AUTOSAR XML (schema 4-1-3)
standard types defined: boolean, sint8, uint16, uint32, uint8, boolean_CompuMethod, boolean_DataConstr, sint8_DataConstr, uint16_DataConstr, uint32_DataConstr, uint8_DataConstr, sint16
package /MICROSAR/Dem_swc/DataTypes
  5 x impl type:
    Dem_DebounceResetStatusType: compu {0=DEM_DEBOUNCE_STATUS_FREEZE, 1=DEM_DEBOUNCE_STATUS_RESET}, range raw 0..255, implementation-data-type=ImplementationDataTypes/uint8
    Dem_DTCFormatType: compu {0=DEM_DTC_FORMAT_OBD, 1=DEM_DTC_FORMAT_UDS, 2=DEM_DTC_FORMAT_J1939}, range raw 0..2, implementation-data-type=ImplementationDataTypes/uint8
    Dem_EventStatusType:
      compu {0=DEM_EVENT_STATUS_PASSED, 1=DEM_EVENT_STATUS_FAILED, 2=DEM_EVENT_STATUS_PREPASSED, 3=DEM_EVENT_STATUS_PREFAILED, 4=DEM_EVENT_STATUS_FDC_THRESHOLD_REACHED, 5=DEM_EVENT_STATUS_PASSED_CONDITIONS_NOT_FULFILLED, 6=DEM_EVENT_STATUS_FAILED_CONDITIONS_NOT_FULFILLED, 7=DEM_EVENT_STATUS_PREPASSED_CONDITIONS_NOT_FULFILLED, 8=DEM_EVENT_STATUS_PREFAILED_CONDITIONS_NOT_FULFILLED}
      range raw 0..255
      implementation-data-type=ImplementationDataTypes/uint8
    Dem_MaxDataValueType: category=ARRAY, sw-calibration-access=READ-ONLY
      element Dem_MaxDataValueTypeElement: array-size=14, array-size-semantics=FIXED-SIZE, implementation-data-type=ImplementationDataTypes/uint8
    Dem_UdsStatusByteType:
      compu {mask 1: 1=DEM_UDS_STATUS_TF (bit 0: TestFailed), mask 2: 2=DEM_UDS_STATUS_TFTOC (bit 1: TestFailedThisOperationCycle), mask 4: 4=DEM_UDS_STATUS_PDTC (bit 2: PendingDTC), mask 8: 8=DEM_UDS_STATUS_CDTC (bit 3: ConfirmedDTC), mask 16: 16=DEM_UDS_STATUS_TNCSLC (bit 4: TestNotCompletedSinceLastClear), mask 32: 32=DEM_UDS_STATUS_TFSLC (bit 5: TestFailedSinceLastClear), mask 64: 64=DEM_UDS_STATUS_TNCTOC (bit 6: TestNotCompletedThisOperationCycle), mask 128: 128=DEM_UDS_STATUS_WIR (bit 7: WarningIndicatorRequested)}
      range raw 0..255
      implementation-data-type=ImplementationDataTypes/uint8
package /MICROSAR/Dem_swc/Interfaces
  client server interface DiagnosticMonitor: is-service=true, service-kind=DIAGNOSTIC-EVENT-MANAGER
    11 x operation:
      GetDTCOfEvent: possible-error=[DEM_E_NO_DTC_AVAILABLE, E_NOT_OK]
        arg DTCFormat: type=Dem_DTCFormatType, direction=IN, server-argument-impl-policy=USE-ARGUMENT-TYPE
        arg DTCOfEvent: type=uint32, direction=OUT, server-argument-impl-policy=USE-ARGUMENT-TYPE
      GetEventExtendedDataRecordEx: possible-error=[DEM_BUFFER_TOO_SMALL, DEM_NO_SUCH_ELEMENT, E_NOT_OK]
        arg RecordNumber: type=ImplementationDataTypes/uint8, direction=IN, server-argument-impl-policy=USE-ARGUMENT-TYPE
        arg DestBuffer: type=Dem_MaxDataValueType, direction=OUT, server-argument-impl-policy=USE-ARGUMENT-TYPE
        arg BufSize: type=ImplementationDataTypes/uint16, direction=INOUT, server-argument-impl-policy=USE-ARGUMENT-TYPE
      GetEventFailed: possible-error=E_NOT_OK
        arg EventFailed: type=ImplementationDataTypes/boolean, direction=OUT, server-argument-impl-policy=USE-ARGUMENT-TYPE
      GetEventFreezeFrameDataEx: possible-error=[DEM_BUFFER_TOO_SMALL, DEM_NO_SUCH_ELEMENT, E_NOT_OK]
        4 x arg, all with server-argument-impl-policy=USE-ARGUMENT-TYPE:
          RecordNumber: type=ImplementationDataTypes/uint8, direction=IN
          DataId: type=ImplementationDataTypes/uint16, direction=IN
          DestBuffer: type=Dem_MaxDataValueType, direction=OUT
          BufSize: type=ImplementationDataTypes/uint16, direction=INOUT
      GetEventStatus: possible-error=E_NOT_OK
        arg UDSStatusByte: type=Dem_UdsStatusByteType, direction=OUT, server-argument-impl-policy=USE-ARGUMENT-TYPE
      GetEventTested: possible-error=E_NOT_OK
        arg EventTested: type=ImplementationDataTypes/boolean, direction=OUT, server-argument-impl-policy=USE-ARGUMENT-TYPE
      GetEventUdsStatus: possible-error=E_NOT_OK
        arg UDSStatusByte: type=Dem_UdsStatusByteType, direction=OUT, server-argument-impl-policy=USE-ARGUMENT-TYPE
      GetFaultDetectionCounter: possible-error=[DEM_E_NO_FDC_AVAILABLE, E_NOT_OK]
        arg FaultDetectionCounter: type=sint8, direction=OUT, server-argument-impl-policy=USE-ARGUMENT-TYPE
      ResetEventDebounceStatus: possible-error=E_NOT_OK
        arg DebounceResetStatus: type=Dem_DebounceResetStatusType, direction=IN, server-argument-impl-policy=USE-ARGUMENT-TYPE
      ResetEventStatus: possible-error=E_NOT_OK
      SetEventStatus: possible-error=E_NOT_OK
        arg EventStatus: type=Dem_EventStatusType, direction=IN, server-argument-impl-policy=USE-ARGUMENT-TYPE
    5 x error:
      DEM_BUFFER_TOO_SMALL: error-code=21
      DEM_E_NO_DTC_AVAILABLE: error-code=10
      DEM_E_NO_FDC_AVAILABLE: error-code=14
      DEM_NO_SUCH_ELEMENT: error-code=48
      E_NOT_OK: error-code=1
package /UAES/ASW/ApplicationDataTypes
  app type T_q0p1_o273p14_DegC_s16: category=VALUE, sw-calibration-access=READ-WRITE, compu {phys=raw*0.1-273.14 for raw -INF..INF; unit DegC}, range raw -32768..32767
package /UAES/ASW/CompuMethods
  compu method CM_boolean: 0=FALSE, 1=TRUE
package /UAES/ASW/DataConstrs
  range DC_boolean: raw 0..1
  range DC_sint16: raw -32768..32767
  range DC_uint16: phys 0..6553.5, raw 0..65535
package /UAES/ASW/DataTypeMappingSets
  data type mapping set DTMS_HVAC_ComCnvTx: data-type-map{application-data-type=T_q0p1_o273p14_DegC_s16, implementation-data-type=sint16}
package /UAES/ASW/PortInterfaces
  147 x sender receiver interface:
    CabinT_t: invalidation-policy{data-element=CabinT_t/Val, handle-invalid=DONT-INVALIDATE}
      data Val: sw-calibration-access=READ-ONLY, type=T_q0p1_o273p14_DegC_s16
    CabinT_tRe: invalidation-policy{data-element=CabinT_tRe/Val, handle-invalid=DONT-INVALIDATE}
      data Val: sw-calibration-access=READ-ONLY, type=T_q0p1_o273p14_DegC_s16
    ComRx_u8UMM_UsageModeSt: invalidation-policy{data-element=ComRx_u8UMM_UsageModeSt/Val, handle-invalid=DONT-INVALIDATE}
      data Val: sw-calibration-access=READ-ONLY, type=ImplementationDataTypes/uint8
    ComTx_bHVAC_LeftExtMirrorHeatActSt: invalidation-policy{data-element=ComTx_bHVAC_LeftExtMirrorHeatActSt/Val, handle-invalid=DONT-INVALIDATE}
      data Val: sw-calibration-access=READ-ONLY, type=ImplementationDataTypes/boolean
    ComTx_bHVAC_ModeServoSt: invalidation-policy{data-element=ComTx_bHVAC_ModeServoSt/Val, handle-invalid=DONT-INVALIDATE}
      data Val: sw-calibration-access=READ-ONLY, type=ImplementationDataTypes/boolean
    ComTx_bHVAC_RearDefrostActSt: invalidation-policy{data-element=ComTx_bHVAC_RearDefrostActSt/Val, handle-invalid=DONT-INVALIDATE}
      data Val: sw-calibration-access=READ-ONLY, type=ImplementationDataTypes/boolean
    ComTx_bHVAC_RightExtMirrorHeatActSt: invalidation-policy{data-element=ComTx_bHVAC_RightExtMirrorHeatActSt/Val, handle-invalid=DONT-INVALIDATE}
      data Val: sw-calibration-access=READ-ONLY, type=ImplementationDataTypes/boolean
    ComTx_bHVAC_RrAMDoorPostionVD: invalidation-policy{data-element=ComTx_bHVAC_RrAMDoorPostionVD/Val, handle-invalid=DONT-INVALIDATE}
      data Val: sw-calibration-access=READ-ONLY, type=ImplementationDataTypes/boolean
    ComTx_bHVAC_RrBlowerPowerSt: invalidation-policy{data-element=ComTx_bHVAC_RrBlowerPowerSt/Val, handle-invalid=DONT-INVALIDATE}
      data Val: sw-calibration-access=READ-ONLY, type=ImplementationDataTypes/boolean
    ComTx_bHVAC_RrModeServoSt: invalidation-policy{data-element=ComTx_bHVAC_RrModeServoSt/Val, handle-invalid=DONT-INVALIDATE}
      data Val: sw-calibration-access=READ-ONLY, type=ImplementationDataTypes/boolean
    ComTx_u16HVAC_DrFaceOutletTemp: invalidation-policy{data-element=ComTx_u16HVAC_DrFaceOutletTemp/Val, handle-invalid=DONT-INVALIDATE}
      data Val: sw-calibration-access=READ-ONLY, type=ImplementationDataTypes/uint16
    ComTx_u16HVAC_DrFootOutletTemp: invalidation-policy{data-element=ComTx_u16HVAC_DrFootOutletTemp/Val, handle-invalid=DONT-INVALIDATE}
      data Val: sw-calibration-access=READ-ONLY, type=ImplementationDataTypes/uint16
    ComTx_u16HVAC_PaFaceOutletTemp: invalidation-policy{data-element=ComTx_u16HVAC_PaFaceOutletTemp/Val, handle-invalid=DONT-INVALIDATE}
      data Val: sw-calibration-access=READ-ONLY, type=ImplementationDataTypes/uint16
    ComTx_u16HVAC_PaFootOutletTemp: invalidation-policy{data-element=ComTx_u16HVAC_PaFootOutletTemp/Val, handle-invalid=DONT-INVALIDATE}
      data Val: sw-calibration-access=READ-ONLY, type=ImplementationDataTypes/uint16
    ComTx_u16HVAC_RawCabinTemp: invalidation-policy{data-element=ComTx_u16HVAC_RawCabinTemp/Val, handle-invalid=DONT-INVALIDATE}
      data Val: sw-calibration-access=READ-ONLY, type=ImplementationDataTypes/uint16
    ComTx_u16HVAC_RawEvaTemp: invalidation-policy{data-element=ComTx_u16HVAC_RawEvaTemp/Val, handle-invalid=DONT-INVALIDATE}
      data Val: sw-calibration-access=READ-ONLY, type=ImplementationDataTypes/uint16
    ComTx_u16HVAC_RrRawCabinTemp: invalidation-policy{data-element=ComTx_u16HVAC_RrRawCabinTemp/Val, handle-invalid=DONT-INVALIDATE}
      data Val: sw-calibration-access=READ-ONLY, type=ImplementationDataTypes/uint16
    ComTx_u16HVAC_RrRawEvaTemp: invalidation-policy{data-element=ComTx_u16HVAC_RrRawEvaTemp/Val, handle-invalid=DONT-INVALIDATE}
      data Val: sw-calibration-access=READ-ONLY, type=ImplementationDataTypes/uint16
    ComTx_u8HVAC_AirCirculationAct: invalidation-policy{data-element=ComTx_u8HVAC_AirCirculationAct/Val, handle-invalid=DONT-INVALIDATE}
      data Val: sw-calibration-access=READ-ONLY, type=ImplementationDataTypes/uint8
    ComTx_u8HVAC_CirculationServoFault: invalidation-policy{data-element=ComTx_u8HVAC_CirculationServoFault/Val, handle-invalid=DONT-INVALIDATE}
      data Val: sw-calibration-access=READ-ONLY, type=ImplementationDataTypes/uint8
    ComTx_u8HVAC_CirculationServoFB: invalidation-policy{data-element=ComTx_u8HVAC_CirculationServoFB/Val, handle-invalid=DONT-INVALIDATE}
      data Val: sw-calibration-access=READ-ONLY, type=ImplementationDataTypes/uint8
    ComTx_u8HVAC_DrAirCirculationAct: invalidation-policy{data-element=ComTx_u8HVAC_DrAirCirculationAct/Val, handle-invalid=DONT-INVALIDATE}
      data Val: sw-calibration-access=READ-ONLY, type=ImplementationDataTypes/uint8
    ComTx_u8HVAC_DrAirCirculationServoFault: invalidation-policy{data-element=ComTx_u8HVAC_DrAirCirculationServoFault/Val, handle-invalid=DONT-INVALIDATE}
      data Val: sw-calibration-access=READ-ONLY, type=ImplementationDataTypes/uint8
    ComTx_u8HVAC_DrAirCirculationServoFB: invalidation-policy{data-element=ComTx_u8HVAC_DrAirCirculationServoFB/Val, handle-invalid=DONT-INVALIDATE}
      data Val: sw-calibration-access=READ-ONLY, type=ImplementationDataTypes/uint8
    ComTx_u8HVAC_DrAMDoorPostionAct: invalidation-policy{data-element=ComTx_u8HVAC_DrAMDoorPostionAct/Val, handle-invalid=DONT-INVALIDATE}
      data Val: sw-calibration-access=READ-ONLY, type=ImplementationDataTypes/uint8
    ComTx_u8HVAC_DrAMServoFault: invalidation-policy{data-element=ComTx_u8HVAC_DrAMServoFault/Val, handle-invalid=DONT-INVALIDATE}
      data Val: sw-calibration-access=READ-ONLY, type=ImplementationDataTypes/uint8
    ComTx_u8HVAC_DrAMServoFB: invalidation-policy{data-element=ComTx_u8HVAC_DrAMServoFB/Val, handle-invalid=DONT-INVALIDATE}
      data Val: sw-calibration-access=READ-ONLY, type=ImplementationDataTypes/uint8
    ComTx_u8HVAC_DrFaceOutletTempFault: invalidation-policy{data-element=ComTx_u8HVAC_DrFaceOutletTempFault/Val, handle-invalid=DONT-INVALIDATE}
      data Val: sw-calibration-access=READ-ONLY, type=ImplementationDataTypes/uint8
    ComTx_u8HVAC_DrFootOutletTempFault: invalidation-policy{data-element=ComTx_u8HVAC_DrFootOutletTempFault/Val, handle-invalid=DONT-INVALIDATE}
      data Val: sw-calibration-access=READ-ONLY, type=ImplementationDataTypes/uint8
    ComTx_u8HVAC_ModeServoFault: invalidation-policy{data-element=ComTx_u8HVAC_ModeServoFault/Val, handle-invalid=DONT-INVALIDATE}
      data Val: sw-calibration-access=READ-ONLY, type=ImplementationDataTypes/uint8
    ComTx_u8HVAC_ModeServoFB: invalidation-policy{data-element=ComTx_u8HVAC_ModeServoFB/Val, handle-invalid=DONT-INVALIDATE}
      data Val: sw-calibration-access=READ-ONLY, type=ImplementationDataTypes/uint8
    ComTx_u8HVAC_PaAirCirculationAct: invalidation-policy{data-element=ComTx_u8HVAC_PaAirCirculationAct/Val, handle-invalid=DONT-INVALIDATE}
      data Val: sw-calibration-access=READ-ONLY, type=ImplementationDataTypes/uint8
    ComTx_u8HVAC_PaAirCirculationServoFault: invalidation-policy{data-element=ComTx_u8HVAC_PaAirCirculationServoFault/Val, handle-invalid=DONT-INVALIDATE}
      data Val: sw-calibration-access=READ-ONLY, type=ImplementationDataTypes/uint8
    ComTx_u8HVAC_PaAirCirculationServoFB: invalidation-policy{data-element=ComTx_u8HVAC_PaAirCirculationServoFB/Val, handle-invalid=DONT-INVALIDATE}
      data Val: sw-calibration-access=READ-ONLY, type=ImplementationDataTypes/uint8
    ComTx_u8HVAC_PaAMDoorPostionAct: invalidation-policy{data-element=ComTx_u8HVAC_PaAMDoorPostionAct/Val, handle-invalid=DONT-INVALIDATE}
      data Val: sw-calibration-access=READ-ONLY, type=ImplementationDataTypes/uint8
    ComTx_u8HVAC_PaAMServoFault: invalidation-policy{data-element=ComTx_u8HVAC_PaAMServoFault/Val, handle-invalid=DONT-INVALIDATE}
      data Val: sw-calibration-access=READ-ONLY, type=ImplementationDataTypes/uint8
    ComTx_u8HVAC_PaAMServoFB: invalidation-policy{data-element=ComTx_u8HVAC_PaAMServoFB/Val, handle-invalid=DONT-INVALIDATE}
      data Val: sw-calibration-access=READ-ONLY, type=ImplementationDataTypes/uint8
    ComTx_u8HVAC_PaFaceOutletTempFault: invalidation-policy{data-element=ComTx_u8HVAC_PaFaceOutletTempFault/Val, handle-invalid=DONT-INVALIDATE}
      data Val: sw-calibration-access=READ-ONLY, type=ImplementationDataTypes/uint8
    ComTx_u8HVAC_PaFootOutletTempFault: invalidation-policy{data-element=ComTx_u8HVAC_PaFootOutletTempFault/Val, handle-invalid=DONT-INVALIDATE}
      data Val: sw-calibration-access=READ-ONLY, type=ImplementationDataTypes/uint8
    ComTx_u8HVAC_RawCabinTempFault: invalidation-policy{data-element=ComTx_u8HVAC_RawCabinTempFault/Val, handle-invalid=DONT-INVALIDATE}
      data Val: sw-calibration-access=READ-ONLY, type=ImplementationDataTypes/uint8
    ComTx_u8HVAC_RawEvaTempFault: invalidation-policy{data-element=ComTx_u8HVAC_RawEvaTempFault/Val, handle-invalid=DONT-INVALIDATE}
      data Val: sw-calibration-access=READ-ONLY, type=ImplementationDataTypes/uint8
    ComTx_u8HVAC_RrAMDoorPostion: invalidation-policy{data-element=ComTx_u8HVAC_RrAMDoorPostion/Val, handle-invalid=DONT-INVALIDATE}
      data Val: sw-calibration-access=READ-ONLY, type=ImplementationDataTypes/uint8
    ComTx_u8HVAC_RrAMDoorPostionAct: invalidation-policy{data-element=ComTx_u8HVAC_RrAMDoorPostionAct/Val, handle-invalid=DONT-INVALIDATE}
      data Val: sw-calibration-access=READ-ONLY, type=ImplementationDataTypes/uint8
    ComTx_u8HVAC_RrAMServoFault: invalidation-policy{data-element=ComTx_u8HVAC_RrAMServoFault/Val, handle-invalid=DONT-INVALIDATE}
      data Val: sw-calibration-access=READ-ONLY, type=ImplementationDataTypes/uint8
    ComTx_u8HVAC_RrAMServoFB: invalidation-policy{data-element=ComTx_u8HVAC_RrAMServoFB/Val, handle-invalid=DONT-INVALIDATE}
      data Val: sw-calibration-access=READ-ONLY, type=ImplementationDataTypes/uint8
    ComTx_u8HVAC_RrModeServoFault: invalidation-policy{data-element=ComTx_u8HVAC_RrModeServoFault/Val, handle-invalid=DONT-INVALIDATE}
      data Val: sw-calibration-access=READ-ONLY, type=ImplementationDataTypes/uint8
    ComTx_u8HVAC_RrModeServoFB: invalidation-policy{data-element=ComTx_u8HVAC_RrModeServoFB/Val, handle-invalid=DONT-INVALIDATE}
      data Val: sw-calibration-access=READ-ONLY, type=ImplementationDataTypes/uint8
    ComTx_u8HVAC_RrRawCabinTempFault: invalidation-policy{data-element=ComTx_u8HVAC_RrRawCabinTempFault/Val, handle-invalid=DONT-INVALIDATE}
      data Val: sw-calibration-access=READ-ONLY, type=ImplementationDataTypes/uint8
    ComTx_u8HVAC_RrRawEvaTempFault: invalidation-policy{data-element=ComTx_u8HVAC_RrRawEvaTempFault/Val, handle-invalid=DONT-INVALIDATE}
      data Val: sw-calibration-access=READ-ONLY, type=ImplementationDataTypes/uint8
    ComTx_u8HVAC_RrWindExitModeAct: invalidation-policy{data-element=ComTx_u8HVAC_RrWindExitModeAct/Val, handle-invalid=DONT-INVALIDATE}
      data Val: sw-calibration-access=READ-ONLY, type=ImplementationDataTypes/uint8
    ComTx_u8HVAC_RrWindExitSpdLvlAct: invalidation-policy{data-element=ComTx_u8HVAC_RrWindExitSpdLvlAct/Val, handle-invalid=DONT-INVALIDATE}
      data Val: sw-calibration-access=READ-ONLY, type=ImplementationDataTypes/uint8
    ComTx_u8HVAC_SolarValueLeft: invalidation-policy{data-element=ComTx_u8HVAC_SolarValueLeft/Val, handle-invalid=DONT-INVALIDATE}
      data Val: sw-calibration-access=READ-ONLY, type=ImplementationDataTypes/uint8
    ComTx_u8HVAC_SolarValueLeftFault: invalidation-policy{data-element=ComTx_u8HVAC_SolarValueLeftFault/Val, handle-invalid=DONT-INVALIDATE}
      data Val: sw-calibration-access=READ-ONLY, type=ImplementationDataTypes/uint8
    ComTx_u8HVAC_SolarValueRight: invalidation-policy{data-element=ComTx_u8HVAC_SolarValueRight/Val, handle-invalid=DONT-INVALIDATE}
      data Val: sw-calibration-access=READ-ONLY, type=ImplementationDataTypes/uint8
    ComTx_u8HVAC_SolarValueRightFault: invalidation-policy{data-element=ComTx_u8HVAC_SolarValueRightFault/Val, handle-invalid=DONT-INVALIDATE}
      data Val: sw-calibration-access=READ-ONLY, type=ImplementationDataTypes/uint8
    ComTx_u8HVAC_WindExitModeAct: invalidation-policy{data-element=ComTx_u8HVAC_WindExitModeAct/Val, handle-invalid=DONT-INVALIDATE}
      data Val: sw-calibration-access=READ-ONLY, type=ImplementationDataTypes/uint8
    ComTx_u8HVAC_WindExitSpdLvlAct: invalidation-policy{data-element=ComTx_u8HVAC_WindExitSpdLvlAct/Val, handle-invalid=DONT-INVALIDATE}
      data Val: sw-calibration-access=READ-ONLY, type=ImplementationDataTypes/uint8
    EvaprT_t: invalidation-policy{data-element=EvaprT_t/Val, handle-invalid=DONT-INVALIDATE}
      data Val: sw-calibration-access=READ-ONLY, type=T_q0p1_o273p14_DegC_s16
    EvaprT_tRe: invalidation-policy{data-element=EvaprT_tRe/Val, handle-invalid=DONT-INVALIDATE}
      data Val: sw-calibration-access=READ-ONLY, type=T_q0p1_o273p14_DegC_s16
    gASI_bCCULostCommon: invalidation-policy{data-element=gASI_bCCULostCommon/Val, handle-invalid=DONT-INVALIDATE}
      data Val: sw-calibration-access=READ-ONLY, type=ImplementationDataTypes/boolean
    gCFG_bCabinTSnsrAvl: invalidation-policy{data-element=gCFG_bCabinTSnsrAvl/Val, handle-invalid=DONT-INVALIDATE}
      data Val: sw-calibration-access=READ-ONLY, type=ImplementationDataTypes/boolean
    gCFG_bReCabinTSnsrAvl: invalidation-policy{data-element=gCFG_bReCabinTSnsrAvl/Val, handle-invalid=DONT-INVALIDATE}
      data Val: sw-calibration-access=READ-ONLY, type=ImplementationDataTypes/boolean
    gCFG_u8AirVentTSnsrTyp: invalidation-policy{data-element=gCFG_u8AirVentTSnsrTyp/Val, handle-invalid=DONT-INVALIDATE}
      data Val: sw-calibration-access=READ-ONLY, type=ImplementationDataTypes/uint8
    gCFG_u8BlowrCtrlFreqTyp: invalidation-policy{data-element=gCFG_u8BlowrCtrlFreqTyp/Val, handle-invalid=DONT-INVALIDATE}
      data Val: sw-calibration-access=READ-ONLY, type=ImplementationDataTypes/uint8
    gCFG_u8BlowrCtrlTyp: invalidation-policy{data-element=gCFG_u8BlowrCtrlTyp/Val, handle-invalid=DONT-INVALIDATE}
      data Val: sw-calibration-access=READ-ONLY, type=ImplementationDataTypes/uint8
    gCFG_u8ReBlowrCtrlFreqTyp: invalidation-policy{data-element=gCFG_u8ReBlowrCtrlFreqTyp/Val, handle-invalid=DONT-INVALIDATE}
      data Val: sw-calibration-access=READ-ONLY, type=ImplementationDataTypes/uint8
    gCFG_u8ReBlowrCtrlTyp: invalidation-policy{data-element=gCFG_u8ReBlowrCtrlTyp/Val, handle-invalid=DONT-INVALIDATE}
      data Val: sw-calibration-access=READ-ONLY, type=ImplementationDataTypes/uint8
    gCFG_u8ReHVACBoxTyp: invalidation-policy{data-element=gCFG_u8ReHVACBoxTyp/Val, handle-invalid=DONT-INVALIDATE}
      data Val: sw-calibration-access=READ-ONLY, type=ImplementationDataTypes/uint8
    gPRM_bHotpumpCfg: invalidation-policy{data-element=gPRM_bHotpumpCfg/Val, handle-invalid=DONT-INVALIDATE}
      data Val: sw-calibration-access=READ-ONLY, type=ImplementationDataTypes/boolean
    gPRM_bSolarSnsrvalidPrm: invalidation-policy{data-element=gPRM_bSolarSnsrvalidPrm/Val, handle-invalid=DONT-INVALIDATE}
      data Val: sw-calibration-access=READ-ONLY, type=ImplementationDataTypes/boolean
    gPRM_u8AirConditionBoxSpecCfg: invalidation-policy{data-element=gPRM_u8AirConditionBoxSpecCfg/Val, handle-invalid=DONT-INVALIDATE}
      data Val: sw-calibration-access=READ-ONLY, type=ImplementationDataTypes/uint8
    gPRM_u8ReAirConditionBoxSpecCfg: invalidation-policy{data-element=gPRM_u8ReAirConditionBoxSpecCfg/Val, handle-invalid=DONT-INVALIDATE}
      data Val: sw-calibration-access=READ-ONLY, type=ImplementationDataTypes/uint8
    gPRM_u8VehicleTypeCfg: invalidation-policy{data-element=gPRM_u8VehicleTypeCfg/Val, handle-invalid=DONT-INVALIDATE}
      data Val: sw-calibration-access=READ-ONLY, range raw 0..255, type=ImplementationDataTypes/uint8
    HvacBlowr_bLPMBlowrEna: invalidation-policy{data-element=HvacBlowr_bLPMBlowrEna/Val, handle-invalid=DONT-INVALIDATE}
      data Val: sw-calibration-access=READ-ONLY, type=ImplementationDataTypes/boolean
    HvacBlowr_bReLPMBlowrEna: invalidation-policy{data-element=HvacBlowr_bReLPMBlowrEna/Val, handle-invalid=DONT-INVALIDATE}
      data Val: sw-calibration-access=READ-ONLY, type=ImplementationDataTypes/boolean
    HvacBlowr_freqPWMBlowr: invalidation-policy{data-element=HvacBlowr_freqPWMBlowr/Val, handle-invalid=DONT-INVALIDATE}
      data Val: sw-calibration-access=READ-ONLY, type=ImplementationDataTypes/uint16
    HvacBlowr_freqRePWMBlowr: invalidation-policy{data-element=HvacBlowr_freqRePWMBlowr/Val, handle-invalid=DONT-INVALIDATE}
      data Val: sw-calibration-access=READ-ONLY, type=ImplementationDataTypes/uint16
    HvacBlowr_prcTarFrntBlowrUds: invalidation-policy{data-element=HvacBlowr_prcTarFrntBlowrUds/Val, handle-invalid=DONT-INVALIDATE}
      data Val: sw-calibration-access=READ-ONLY, type=ImplementationDataTypes/uint8
    HvacBlowr_ratLPMBlowr: invalidation-policy{data-element=HvacBlowr_ratLPMBlowr/Val, handle-invalid=DONT-INVALIDATE}
      data Val: sw-calibration-access=READ-ONLY, type=ImplementationDataTypes/uint16
    HvacBlowr_ratPWMBlowr: invalidation-policy{data-element=HvacBlowr_ratPWMBlowr/Val, handle-invalid=DONT-INVALIDATE}
      data Val: sw-calibration-access=READ-ONLY, type=ImplementationDataTypes/uint16
    HvacBlowr_ratReLPMBlowr: invalidation-policy{data-element=HvacBlowr_ratReLPMBlowr/Val, handle-invalid=DONT-INVALIDATE}
      data Val: sw-calibration-access=READ-ONLY, type=ImplementationDataTypes/uint16
    HvacBlowr_ratRePWMBlowr: invalidation-policy{data-element=HvacBlowr_ratRePWMBlowr/Val, handle-invalid=DONT-INVALIDATE}
      data Val: sw-calibration-access=READ-ONLY, type=ImplementationDataTypes/uint16
    HvacBlowr_stReWindExitSpdLvlAct: invalidation-policy{data-element=HvacBlowr_stReWindExitSpdLvlAct/Val, handle-invalid=DONT-INVALIDATE}
      data Val: sw-calibration-access=READ-ONLY, type=ImplementationDataTypes/uint8
    HvacBlowr_stWindExitSpdLvlAct: invalidation-policy{data-element=HvacBlowr_stWindExitSpdLvlAct/Val, handle-invalid=DONT-INVALIDATE}
      data Val: sw-calibration-access=READ-ONLY, type=ImplementationDataTypes/uint16
    HvacBlowr_uRawLPMFb: invalidation-policy{data-element=HvacBlowr_uRawLPMFb/Val, handle-invalid=DONT-INVALIDATE}
      data Val: sw-calibration-access=READ-ONLY, type=ImplementationDataTypes/uint16
    HvacBlowr_uTarFrntBlowrUds: invalidation-policy{data-element=HvacBlowr_uTarFrntBlowrUds/Val, handle-invalid=DONT-INVALIDATE}
      data Val: sw-calibration-access=READ-ONLY, type=ImplementationDataTypes/uint8
    HvacDampr_stDrvrMixMotAct: invalidation-policy{data-element=HvacDampr_stDrvrMixMotAct/Val, handle-invalid=DONT-INVALIDATE}
      data Val: sw-calibration-access=READ-ONLY, type=ImplementationDataTypes/uint8
    HvacDampr_stDrvrMixMotDir: invalidation-policy{data-element=HvacDampr_stDrvrMixMotDir/Val, handle-invalid=DONT-INVALIDATE}
      data Val: sw-calibration-access=READ-ONLY, type=ImplementationDataTypes/uint8
    HvacDampr_stDrvrMixMotFlt: invalidation-policy{data-element=HvacDampr_stDrvrMixMotFlt/Val, handle-invalid=DONT-INVALIDATE}
      data Val: sw-calibration-access=READ-ONLY, type=ImplementationDataTypes/uint8
    HvacDampr_stDrvrMixMotRunng: invalidation-policy{data-element=HvacDampr_stDrvrMixMotRunng/Val, handle-invalid=DONT-INVALIDATE}
      data Val: sw-calibration-access=READ-ONLY, type=ImplementationDataTypes/uint8
    HvacDampr_stDrvrRcrltnMotAct: invalidation-policy{data-element=HvacDampr_stDrvrRcrltnMotAct/Val, handle-invalid=DONT-INVALIDATE}
      data Val: sw-calibration-access=READ-ONLY, type=ImplementationDataTypes/uint8
    HvacDampr_stDrvrRcrltnMotDir: invalidation-policy{data-element=HvacDampr_stDrvrRcrltnMotDir/Val, handle-invalid=DONT-INVALIDATE}
      data Val: sw-calibration-access=READ-ONLY, type=ImplementationDataTypes/uint8
    HvacDampr_stDrvrRcrltnMotFlt: invalidation-policy{data-element=HvacDampr_stDrvrRcrltnMotFlt/Val, handle-invalid=DONT-INVALIDATE}
      data Val: sw-calibration-access=READ-ONLY, type=ImplementationDataTypes/uint8
    HvacDampr_stDrvrRcrltnMotRunng: invalidation-policy{data-element=HvacDampr_stDrvrRcrltnMotRunng/Val, handle-invalid=DONT-INVALIDATE}
      data Val: sw-calibration-access=READ-ONLY, type=ImplementationDataTypes/uint8
    HvacDampr_stModMotAct: invalidation-policy{data-element=HvacDampr_stModMotAct/Val, handle-invalid=DONT-INVALIDATE}
      data Val: sw-calibration-access=READ-ONLY, type=ImplementationDataTypes/uint8
    HvacDampr_stModMotDir: invalidation-policy{data-element=HvacDampr_stModMotDir/Val, handle-invalid=DONT-INVALIDATE}
      data Val: sw-calibration-access=READ-ONLY, type=ImplementationDataTypes/uint8
    HvacDampr_stModMotFlt: invalidation-policy{data-element=HvacDampr_stModMotFlt/Val, handle-invalid=DONT-INVALIDATE}
      data Val: sw-calibration-access=READ-ONLY, type=ImplementationDataTypes/uint8
    HvacDampr_stModMotRunng: invalidation-policy{data-element=HvacDampr_stModMotRunng/Val, handle-invalid=DONT-INVALIDATE}
      data Val: sw-calibration-access=READ-ONLY, type=ImplementationDataTypes/uint8
    HvacDampr_stPassMixMotAct: invalidation-policy{data-element=HvacDampr_stPassMixMotAct/Val, handle-invalid=DONT-INVALIDATE}
      data Val: sw-calibration-access=READ-ONLY, type=ImplementationDataTypes/uint8
    HvacDampr_stPassMixMotDir: invalidation-policy{data-element=HvacDampr_stPassMixMotDir/Val, handle-invalid=DONT-INVALIDATE}
      data Val: sw-calibration-access=READ-ONLY, type=ImplementationDataTypes/uint8
    HvacDampr_stPassMixMotFlt: invalidation-policy{data-element=HvacDampr_stPassMixMotFlt/Val, handle-invalid=DONT-INVALIDATE}
      data Val: sw-calibration-access=READ-ONLY, type=ImplementationDataTypes/uint8
    HvacDampr_stPassMixMotRunng: invalidation-policy{data-element=HvacDampr_stPassMixMotRunng/Val, handle-invalid=DONT-INVALIDATE}
      data Val: sw-calibration-access=READ-ONLY, type=ImplementationDataTypes/uint8
    HvacDampr_stPassRcrltnMotAct: invalidation-policy{data-element=HvacDampr_stPassRcrltnMotAct/Val, handle-invalid=DONT-INVALIDATE}
      data Val: sw-calibration-access=READ-ONLY, type=ImplementationDataTypes/uint8
    HvacDampr_stPassRcrltnMotDir: invalidation-policy{data-element=HvacDampr_stPassRcrltnMotDir/Val, handle-invalid=DONT-INVALIDATE}
      data Val: sw-calibration-access=READ-ONLY, type=ImplementationDataTypes/uint8
    HvacDampr_stPassRcrltnMotFlt: invalidation-policy{data-element=HvacDampr_stPassRcrltnMotFlt/Val, handle-invalid=DONT-INVALIDATE}
      data Val: sw-calibration-access=READ-ONLY, type=ImplementationDataTypes/uint8
    HvacDampr_stPassRcrltnMotRunng: invalidation-policy{data-element=HvacDampr_stPassRcrltnMotRunng/Val, handle-invalid=DONT-INVALIDATE}
      data Val: sw-calibration-access=READ-ONLY, type=ImplementationDataTypes/uint8
    HvacDampr_stRcrltnMotAct: invalidation-policy{data-element=HvacDampr_stRcrltnMotAct/Val, handle-invalid=DONT-INVALIDATE}
      data Val: sw-calibration-access=READ-ONLY, type=ImplementationDataTypes/uint8
    HvacDampr_stRcrltnMotDir: invalidation-policy{data-element=HvacDampr_stRcrltnMotDir/Val, handle-invalid=DONT-INVALIDATE}
      data Val: sw-calibration-access=READ-ONLY, type=ImplementationDataTypes/uint8
    HvacDampr_stRcrltnMotFlt: invalidation-policy{data-element=HvacDampr_stRcrltnMotFlt/Val, handle-invalid=DONT-INVALIDATE}
      data Val: sw-calibration-access=READ-ONLY, type=ImplementationDataTypes/uint8
    HvacDampr_stRcrltnMotRunng: invalidation-policy{data-element=HvacDampr_stRcrltnMotRunng/Val, handle-invalid=DONT-INVALIDATE}
      data Val: sw-calibration-access=READ-ONLY, type=ImplementationDataTypes/uint8
    HvacDampr_stReMixMotAct: invalidation-policy{data-element=HvacDampr_stReMixMotAct/Val, handle-invalid=DONT-INVALIDATE}
      data Val: sw-calibration-access=READ-ONLY, type=ImplementationDataTypes/uint8
    HvacDampr_stReMixMotDir: invalidation-policy{data-element=HvacDampr_stReMixMotDir/Val, handle-invalid=DONT-INVALIDATE}
      data Val: sw-calibration-access=READ-ONLY, type=ImplementationDataTypes/uint8
    HvacDampr_stReMixMotFlt: invalidation-policy{data-element=HvacDampr_stReMixMotFlt/Val, handle-invalid=DONT-INVALIDATE}
      data Val: sw-calibration-access=READ-ONLY, type=ImplementationDataTypes/uint8
    HvacDampr_stReMixMotRunng: invalidation-policy{data-element=HvacDampr_stReMixMotRunng/Val, handle-invalid=DONT-INVALIDATE}
      data Val: sw-calibration-access=READ-ONLY, type=ImplementationDataTypes/uint8
    HvacDampr_stReModMotAct: invalidation-policy{data-element=HvacDampr_stReModMotAct/Val, handle-invalid=DONT-INVALIDATE}
      data Val: sw-calibration-access=READ-ONLY, type=ImplementationDataTypes/uint8
    HvacDampr_stReModMotDir: invalidation-policy{data-element=HvacDampr_stReModMotDir/Val, handle-invalid=DONT-INVALIDATE}
      data Val: sw-calibration-access=READ-ONLY, type=ImplementationDataTypes/uint8
    HvacDampr_stReModMotFlt: invalidation-policy{data-element=HvacDampr_stReModMotFlt/Val, handle-invalid=DONT-INVALIDATE}
      data Val: sw-calibration-access=READ-ONLY, type=ImplementationDataTypes/uint8
    HvacDampr_stReModMotRunng: invalidation-policy{data-element=HvacDampr_stReModMotRunng/Val, handle-invalid=DONT-INVALIDATE}
      data Val: sw-calibration-access=READ-ONLY, type=ImplementationDataTypes/uint8
    HvacDampr_uActDrvrRcrltnMotUds: invalidation-policy{data-element=HvacDampr_uActDrvrRcrltnMotUds/Val, handle-invalid=DONT-INVALIDATE}
      data Val: sw-calibration-access=READ-ONLY, type=ImplementationDataTypes/uint8
    HvacDampr_uActModMotUds: invalidation-policy{data-element=HvacDampr_uActModMotUds/Val, handle-invalid=DONT-INVALIDATE}
      data Val: sw-calibration-access=READ-ONLY, type=ImplementationDataTypes/uint8
    HvacDampr_uActPassMixMotUds: invalidation-policy{data-element=HvacDampr_uActPassMixMotUds/Val, handle-invalid=DONT-INVALIDATE}
      data Val: sw-calibration-access=READ-ONLY, type=ImplementationDataTypes/uint8
    HvacDampr_uActPassRcrltnMotUds: invalidation-policy{data-element=HvacDampr_uActPassRcrltnMotUds/Val, handle-invalid=DONT-INVALIDATE}
      data Val: sw-calibration-access=READ-ONLY, type=ImplementationDataTypes/uint8
    HvacDampr_uActPsgrMixMotUds: invalidation-policy{data-element=HvacDampr_uActPsgrMixMotUds/Val, handle-invalid=DONT-INVALIDATE}
      data Val: sw-calibration-access=READ-ONLY, type=ImplementationDataTypes/uint8
    HvacDampr_uActRcrltnMotUds: invalidation-policy{data-element=HvacDampr_uActRcrltnMotUds/Val, handle-invalid=DONT-INVALIDATE}
      data Val: sw-calibration-access=READ-ONLY, type=ImplementationDataTypes/uint8
    HvacDampr_uDrvrMixMotFb: invalidation-policy{data-element=HvacDampr_uDrvrMixMotFb/Val, handle-invalid=DONT-INVALIDATE}
      data Val: sw-calibration-access=READ-ONLY, type=ImplementationDataTypes/uint16
    HvacDampr_uDrvrRcrltnMotFb: invalidation-policy{data-element=HvacDampr_uDrvrRcrltnMotFb/Val, handle-invalid=DONT-INVALIDATE}
      data Val: sw-calibration-access=READ-ONLY, type=ImplementationDataTypes/uint16
    HvacDampr_uModMotFb: invalidation-policy{data-element=HvacDampr_uModMotFb/Val, handle-invalid=DONT-INVALIDATE}
      data Val: sw-calibration-access=READ-ONLY, type=ImplementationDataTypes/uint16
    HvacDampr_uPassMixMotFb: invalidation-policy{data-element=HvacDampr_uPassMixMotFb/Val, handle-invalid=DONT-INVALIDATE}
      data Val: sw-calibration-access=READ-ONLY, type=ImplementationDataTypes/uint16
    HvacDampr_uPassRcrltnMotFb: invalidation-policy{data-element=HvacDampr_uPassRcrltnMotFb/Val, handle-invalid=DONT-INVALIDATE}
      data Val: sw-calibration-access=READ-ONLY, type=ImplementationDataTypes/uint16
    HvacDampr_uRcrltnMotFb: invalidation-policy{data-element=HvacDampr_uRcrltnMotFb/Val, handle-invalid=DONT-INVALIDATE}
      data Val: sw-calibration-access=READ-ONLY, type=ImplementationDataTypes/uint16
    HvacDampr_uReMixMotFb: invalidation-policy{data-element=HvacDampr_uReMixMotFb/Val, handle-invalid=DONT-INVALIDATE}
      data Val: sw-calibration-access=READ-ONLY, type=ImplementationDataTypes/uint16
    HvacDampr_uReModMotFb: invalidation-policy{data-element=HvacDampr_uReModMotFb/Val, handle-invalid=DONT-INVALIDATE}
      data Val: sw-calibration-access=READ-ONLY, type=ImplementationDataTypes/uint16
    HvacDampr_uTarDrvrMixMotUds: invalidation-policy{data-element=HvacDampr_uTarDrvrMixMotUds/Val, handle-invalid=DONT-INVALIDATE}
      data Val: sw-calibration-access=READ-ONLY, type=ImplementationDataTypes/uint8
    HvacDampr_uTarDrvrRcrltnMotUds: invalidation-policy{data-element=HvacDampr_uTarDrvrRcrltnMotUds/Val, handle-invalid=DONT-INVALIDATE}
      data Val: sw-calibration-access=READ-ONLY, type=ImplementationDataTypes/uint8
    HvacDampr_uTarModMotUds: invalidation-policy{data-element=HvacDampr_uTarModMotUds/Val, handle-invalid=DONT-INVALIDATE}
      data Val: sw-calibration-access=READ-ONLY, type=ImplementationDataTypes/uint8
    HvacDampr_uTarPassMixMotUds: invalidation-policy{data-element=HvacDampr_uTarPassMixMotUds/Val, handle-invalid=DONT-INVALIDATE}
      data Val: sw-calibration-access=READ-ONLY, type=ImplementationDataTypes/uint8
    HvacDampr_uTarPassRcrltnMotUds: invalidation-policy{data-element=HvacDampr_uTarPassRcrltnMotUds/Val, handle-invalid=DONT-INVALIDATE}
      data Val: sw-calibration-access=READ-ONLY, type=ImplementationDataTypes/uint8
    HvacDampr_uTarRcrltnMotUds: invalidation-policy{data-element=HvacDampr_uTarRcrltnMotUds/Val, handle-invalid=DONT-INVALIDATE}
      data Val: sw-calibration-access=READ-ONLY, type=ImplementationDataTypes/uint8
    HvacVentT_tDrvrFaceVent: invalidation-policy{data-element=HvacVentT_tDrvrFaceVent/Val, handle-invalid=DONT-INVALIDATE}
      data Val: sw-calibration-access=READ-ONLY, type=T_q0p1_o273p14_DegC_s16
    HvacVentT_tDrvrFootVent: invalidation-policy{data-element=HvacVentT_tDrvrFootVent/Val, handle-invalid=DONT-INVALIDATE}
      data Val: sw-calibration-access=READ-ONLY, type=T_q0p1_o273p14_DegC_s16
    HvacVentT_tPassFaceVent: invalidation-policy{data-element=HvacVentT_tPassFaceVent/Val, handle-invalid=DONT-INVALIDATE}
      data Val: sw-calibration-access=READ-ONLY, type=T_q0p1_o273p14_DegC_s16
    HvacVentT_tPassFootVent: invalidation-policy{data-element=HvacVentT_tPassFootVent/Val, handle-invalid=DONT-INVALIDATE}
      data Val: sw-calibration-access=READ-ONLY, type=T_q0p1_o273p14_DegC_s16
    ReMirrHeatg_stPsLe: invalidation-policy{data-element=ReMirrHeatg_stPsLe/Val, handle-invalid=DONT-INVALIDATE}
      data Val: sw-calibration-access=READ-ONLY, type=ImplementationDataTypes/uint8
    ReMirrHeatg_stPsRi: invalidation-policy{data-element=ReMirrHeatg_stPsRi/Val, handle-invalid=DONT-INVALIDATE}
      data Val: sw-calibration-access=READ-ONLY, type=ImplementationDataTypes/uint8
    SolarSnsr_riLe: invalidation-policy{data-element=SolarSnsr_riLe/Val, handle-invalid=DONT-INVALIDATE}
      data Val: sw-calibration-access=READ-ONLY, type=ImplementationDataTypes/uint16
    SolarSnsr_riRi: invalidation-policy{data-element=SolarSnsr_riRi/Val, handle-invalid=DONT-INVALIDATE}
      data Val: sw-calibration-access=READ-ONLY, type=ImplementationDataTypes/uint16
    WndshdHeatg_stPsRe: invalidation-policy{data-element=WndshdHeatg_stPsRe/Val, handle-invalid=DONT-INVALIDATE}
      data Val: sw-calibration-access=READ-ONLY, type=ImplementationDataTypes/uint8
package /UAES/ASW/SwComponentTypes
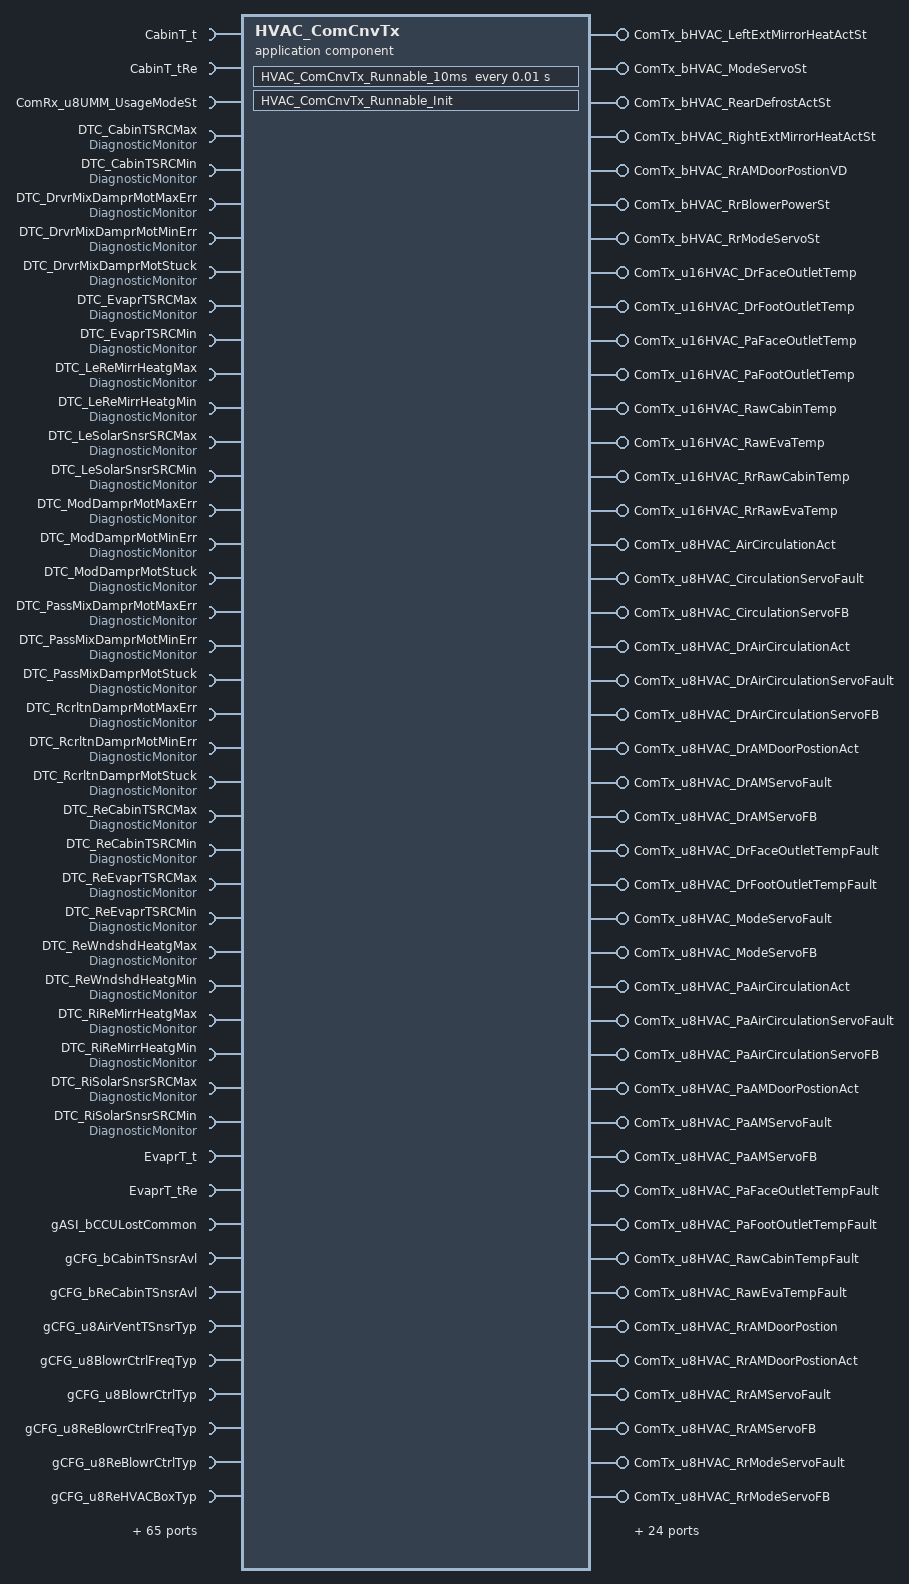
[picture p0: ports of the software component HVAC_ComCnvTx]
  application sw component type HVAC_ComCnvTx
    68 x provide port:
      ComTx_bHVAC_LeftExtMirrorHeatActSt: nonqueued-sender-com-spec{data-element=ComTx_bHVAC_LeftExtMirrorHeatActSt/Val, init-value=0}, provided-interface=ComTx_bHVAC_LeftExtMirrorHeatActSt
      ComTx_bHVAC_ModeServoSt: nonqueued-sender-com-spec{data-element=ComTx_bHVAC_ModeServoSt/Val, init-value=0}, provided-interface=ComTx_bHVAC_ModeServoSt
      ComTx_bHVAC_RearDefrostActSt: nonqueued-sender-com-spec{data-element=ComTx_bHVAC_RearDefrostActSt/Val, init-value=0}, provided-interface=ComTx_bHVAC_RearDefrostActSt
      ComTx_bHVAC_RightExtMirrorHeatActSt: nonqueued-sender-com-spec{data-element=ComTx_bHVAC_RightExtMirrorHeatActSt/Val, init-value=0}, provided-interface=ComTx_bHVAC_RightExtMirrorHeatActSt
      ComTx_bHVAC_RrAMDoorPostionVD: nonqueued-sender-com-spec{data-element=ComTx_bHVAC_RrAMDoorPostionVD/Val, init-value=0}, provided-interface=ComTx_bHVAC_RrAMDoorPostionVD
      ComTx_bHVAC_RrBlowerPowerSt: nonqueued-sender-com-spec{data-element=ComTx_bHVAC_RrBlowerPowerSt/Val, init-value=0}, provided-interface=ComTx_bHVAC_RrBlowerPowerSt
      ComTx_bHVAC_RrModeServoSt: nonqueued-sender-com-spec{data-element=ComTx_bHVAC_RrModeServoSt/Val, init-value=0}, provided-interface=ComTx_bHVAC_RrModeServoSt
      ComTx_u16HVAC_DrFaceOutletTemp: nonqueued-sender-com-spec{data-element=ComTx_u16HVAC_DrFaceOutletTemp/Val, init-value=0}, provided-interface=ComTx_u16HVAC_DrFaceOutletTemp
      ComTx_u16HVAC_DrFootOutletTemp: nonqueued-sender-com-spec{data-element=ComTx_u16HVAC_DrFootOutletTemp/Val, init-value=0}, provided-interface=ComTx_u16HVAC_DrFootOutletTemp
      ComTx_u16HVAC_PaFaceOutletTemp: nonqueued-sender-com-spec{data-element=ComTx_u16HVAC_PaFaceOutletTemp/Val, init-value=0}, provided-interface=ComTx_u16HVAC_PaFaceOutletTemp
      ComTx_u16HVAC_PaFootOutletTemp: nonqueued-sender-com-spec{data-element=ComTx_u16HVAC_PaFootOutletTemp/Val, init-value=0}, provided-interface=ComTx_u16HVAC_PaFootOutletTemp
      ComTx_u16HVAC_RawCabinTemp: nonqueued-sender-com-spec{data-element=ComTx_u16HVAC_RawCabinTemp/Val, init-value=0}, provided-interface=ComTx_u16HVAC_RawCabinTemp
      ComTx_u16HVAC_RawEvaTemp: nonqueued-sender-com-spec{data-element=ComTx_u16HVAC_RawEvaTemp/Val, init-value=0}, provided-interface=ComTx_u16HVAC_RawEvaTemp
      ComTx_u16HVAC_RrRawCabinTemp: nonqueued-sender-com-spec{data-element=ComTx_u16HVAC_RrRawCabinTemp/Val, init-value=0}, provided-interface=ComTx_u16HVAC_RrRawCabinTemp
      ComTx_u16HVAC_RrRawEvaTemp: nonqueued-sender-com-spec{data-element=ComTx_u16HVAC_RrRawEvaTemp/Val, init-value=0}, provided-interface=ComTx_u16HVAC_RrRawEvaTemp
      ComTx_u8HVAC_AirCirculationAct: nonqueued-sender-com-spec{data-element=ComTx_u8HVAC_AirCirculationAct/Val, init-value=0}, provided-interface=ComTx_u8HVAC_AirCirculationAct
      ComTx_u8HVAC_CirculationServoFault: nonqueued-sender-com-spec{data-element=ComTx_u8HVAC_CirculationServoFault/Val, init-value=0}, provided-interface=ComTx_u8HVAC_CirculationServoFault
      ComTx_u8HVAC_CirculationServoFB: nonqueued-sender-com-spec{data-element=ComTx_u8HVAC_CirculationServoFB/Val, init-value=0}, provided-interface=ComTx_u8HVAC_CirculationServoFB
      ComTx_u8HVAC_DrAirCirculationAct: nonqueued-sender-com-spec{data-element=ComTx_u8HVAC_DrAirCirculationAct/Val, init-value=0}, provided-interface=ComTx_u8HVAC_DrAirCirculationAct
      ComTx_u8HVAC_DrAirCirculationServoFault: nonqueued-sender-com-spec{data-element=ComTx_u8HVAC_DrAirCirculationServoFault/Val, init-value=0}, provided-interface=ComTx_u8HVAC_DrAirCirculationServoFault
      ComTx_u8HVAC_DrAirCirculationServoFB: nonqueued-sender-com-spec{data-element=ComTx_u8HVAC_DrAirCirculationServoFB/Val, init-value=0}, provided-interface=ComTx_u8HVAC_DrAirCirculationServoFB
      ComTx_u8HVAC_DrAMDoorPostionAct: nonqueued-sender-com-spec{data-element=ComTx_u8HVAC_DrAMDoorPostionAct/Val, init-value=0}, provided-interface=ComTx_u8HVAC_DrAMDoorPostionAct
      ComTx_u8HVAC_DrAMServoFault: nonqueued-sender-com-spec{data-element=ComTx_u8HVAC_DrAMServoFault/Val, init-value=0}, provided-interface=ComTx_u8HVAC_DrAMServoFault
      ComTx_u8HVAC_DrAMServoFB: nonqueued-sender-com-spec{data-element=ComTx_u8HVAC_DrAMServoFB/Val, init-value=0}, provided-interface=ComTx_u8HVAC_DrAMServoFB
      ComTx_u8HVAC_DrFaceOutletTempFault: nonqueued-sender-com-spec{data-element=ComTx_u8HVAC_DrFaceOutletTempFault/Val, init-value=0}, provided-interface=ComTx_u8HVAC_DrFaceOutletTempFault
      ComTx_u8HVAC_DrFootOutletTempFault: nonqueued-sender-com-spec{data-element=ComTx_u8HVAC_DrFootOutletTempFault/Val, init-value=0}, provided-interface=ComTx_u8HVAC_DrFootOutletTempFault
      ComTx_u8HVAC_ModeServoFault: nonqueued-sender-com-spec{data-element=ComTx_u8HVAC_ModeServoFault/Val, init-value=0}, provided-interface=ComTx_u8HVAC_ModeServoFault
      ComTx_u8HVAC_ModeServoFB: nonqueued-sender-com-spec{data-element=ComTx_u8HVAC_ModeServoFB/Val, init-value=0}, provided-interface=ComTx_u8HVAC_ModeServoFB
      ComTx_u8HVAC_PaAirCirculationAct: nonqueued-sender-com-spec{data-element=ComTx_u8HVAC_PaAirCirculationAct/Val, init-value=0}, provided-interface=ComTx_u8HVAC_PaAirCirculationAct
      ComTx_u8HVAC_PaAirCirculationServoFault: nonqueued-sender-com-spec{data-element=ComTx_u8HVAC_PaAirCirculationServoFault/Val, init-value=0}, provided-interface=ComTx_u8HVAC_PaAirCirculationServoFault
      ComTx_u8HVAC_PaAirCirculationServoFB: nonqueued-sender-com-spec{data-element=ComTx_u8HVAC_PaAirCirculationServoFB/Val, init-value=0}, provided-interface=ComTx_u8HVAC_PaAirCirculationServoFB
      ComTx_u8HVAC_PaAMDoorPostionAct: nonqueued-sender-com-spec{data-element=ComTx_u8HVAC_PaAMDoorPostionAct/Val, init-value=0}, provided-interface=ComTx_u8HVAC_PaAMDoorPostionAct
      ComTx_u8HVAC_PaAMServoFault: nonqueued-sender-com-spec{data-element=ComTx_u8HVAC_PaAMServoFault/Val, init-value=0}, provided-interface=ComTx_u8HVAC_PaAMServoFault
      ComTx_u8HVAC_PaAMServoFB: nonqueued-sender-com-spec{data-element=ComTx_u8HVAC_PaAMServoFB/Val, init-value=0}, provided-interface=ComTx_u8HVAC_PaAMServoFB
      ComTx_u8HVAC_PaFaceOutletTempFault: nonqueued-sender-com-spec{data-element=ComTx_u8HVAC_PaFaceOutletTempFault/Val, init-value=0}, provided-interface=ComTx_u8HVAC_PaFaceOutletTempFault
      ComTx_u8HVAC_PaFootOutletTempFault: nonqueued-sender-com-spec{data-element=ComTx_u8HVAC_PaFootOutletTempFault/Val, init-value=0}, provided-interface=ComTx_u8HVAC_PaFootOutletTempFault
      ComTx_u8HVAC_RawCabinTempFault: nonqueued-sender-com-spec{data-element=ComTx_u8HVAC_RawCabinTempFault/Val, init-value=0}, provided-interface=ComTx_u8HVAC_RawCabinTempFault
      ComTx_u8HVAC_RawEvaTempFault: nonqueued-sender-com-spec{data-element=ComTx_u8HVAC_RawEvaTempFault/Val, init-value=0}, provided-interface=ComTx_u8HVAC_RawEvaTempFault
      ComTx_u8HVAC_RrAMDoorPostion: nonqueued-sender-com-spec{data-element=ComTx_u8HVAC_RrAMDoorPostion/Val, init-value=0}, provided-interface=ComTx_u8HVAC_RrAMDoorPostion
      ComTx_u8HVAC_RrAMDoorPostionAct: nonqueued-sender-com-spec{data-element=ComTx_u8HVAC_RrAMDoorPostionAct/Val, init-value=0}, provided-interface=ComTx_u8HVAC_RrAMDoorPostionAct
      ComTx_u8HVAC_RrAMServoFault: nonqueued-sender-com-spec{data-element=ComTx_u8HVAC_RrAMServoFault/Val, init-value=0}, provided-interface=ComTx_u8HVAC_RrAMServoFault
      ComTx_u8HVAC_RrAMServoFB: nonqueued-sender-com-spec{data-element=ComTx_u8HVAC_RrAMServoFB/Val, init-value=0}, provided-interface=ComTx_u8HVAC_RrAMServoFB
      ComTx_u8HVAC_RrModeServoFault: nonqueued-sender-com-spec{data-element=ComTx_u8HVAC_RrModeServoFault/Val, init-value=0}, provided-interface=ComTx_u8HVAC_RrModeServoFault
      ComTx_u8HVAC_RrModeServoFB: nonqueued-sender-com-spec{data-element=ComTx_u8HVAC_RrModeServoFB/Val, init-value=0}, provided-interface=ComTx_u8HVAC_RrModeServoFB
      ComTx_u8HVAC_RrRawCabinTempFault: nonqueued-sender-com-spec{data-element=ComTx_u8HVAC_RrRawCabinTempFault/Val, init-value=0}, provided-interface=ComTx_u8HVAC_RrRawCabinTempFault
      ComTx_u8HVAC_RrRawEvaTempFault: nonqueued-sender-com-spec{data-element=ComTx_u8HVAC_RrRawEvaTempFault/Val, init-value=0}, provided-interface=ComTx_u8HVAC_RrRawEvaTempFault
      ComTx_u8HVAC_RrWindExitModeAct: nonqueued-sender-com-spec{data-element=ComTx_u8HVAC_RrWindExitModeAct/Val, init-value=0}, provided-interface=ComTx_u8HVAC_RrWindExitModeAct
      ComTx_u8HVAC_RrWindExitSpdLvlAct: nonqueued-sender-com-spec{data-element=ComTx_u8HVAC_RrWindExitSpdLvlAct/Val, init-value=0}, provided-interface=ComTx_u8HVAC_RrWindExitSpdLvlAct
      ComTx_u8HVAC_SolarValueLeft: nonqueued-sender-com-spec{data-element=ComTx_u8HVAC_SolarValueLeft/Val, init-value=0}, provided-interface=ComTx_u8HVAC_SolarValueLeft
      ComTx_u8HVAC_SolarValueLeftFault: nonqueued-sender-com-spec{data-element=ComTx_u8HVAC_SolarValueLeftFault/Val, init-value=0}, provided-interface=ComTx_u8HVAC_SolarValueLeftFault
      ComTx_u8HVAC_SolarValueRight: nonqueued-sender-com-spec{data-element=ComTx_u8HVAC_SolarValueRight/Val, init-value=0}, provided-interface=ComTx_u8HVAC_SolarValueRight
      ComTx_u8HVAC_SolarValueRightFault: nonqueued-sender-com-spec{data-element=ComTx_u8HVAC_SolarValueRightFault/Val, init-value=0}, provided-interface=ComTx_u8HVAC_SolarValueRightFault
      ComTx_u8HVAC_WindExitModeAct: nonqueued-sender-com-spec{data-element=ComTx_u8HVAC_WindExitModeAct/Val, init-value=0}, provided-interface=ComTx_u8HVAC_WindExitModeAct
      ComTx_u8HVAC_WindExitSpdLvlAct: nonqueued-sender-com-spec{data-element=ComTx_u8HVAC_WindExitSpdLvlAct/Val, init-value=0}, provided-interface=ComTx_u8HVAC_WindExitSpdLvlAct
      HvacBlowr_prcTarFrntBlowrUds: nonqueued-sender-com-spec{data-element=HvacBlowr_prcTarFrntBlowrUds/Val, init-value=0}, provided-interface=HvacBlowr_prcTarFrntBlowrUds
      HvacBlowr_uTarFrntBlowrUds: nonqueued-sender-com-spec{data-element=HvacBlowr_uTarFrntBlowrUds/Val, init-value=0}, provided-interface=HvacBlowr_uTarFrntBlowrUds
      HvacDampr_uActDrvrRcrltnMotUds: nonqueued-sender-com-spec{data-element=HvacDampr_uActDrvrRcrltnMotUds/Val, init-value=0}, provided-interface=HvacDampr_uActDrvrRcrltnMotUds
      HvacDampr_uActModMotUds: nonqueued-sender-com-spec{data-element=HvacDampr_uActModMotUds/Val, init-value=0}, provided-interface=HvacDampr_uActModMotUds
      HvacDampr_uActPassMixMotUds: nonqueued-sender-com-spec{data-element=HvacDampr_uActPassMixMotUds/Val, init-value=0}, provided-interface=HvacDampr_uActPassMixMotUds
      HvacDampr_uActPassRcrltnMotUds: nonqueued-sender-com-spec{data-element=HvacDampr_uActPassRcrltnMotUds/Val, init-value=0}, provided-interface=HvacDampr_uActPassRcrltnMotUds
      HvacDampr_uActPsgrMixMotUds: nonqueued-sender-com-spec{data-element=HvacDampr_uActPsgrMixMotUds/Val, init-value=0}, provided-interface=HvacDampr_uActPsgrMixMotUds
      HvacDampr_uActRcrltnMotUds: nonqueued-sender-com-spec{data-element=HvacDampr_uActRcrltnMotUds/Val, init-value=0}, provided-interface=HvacDampr_uActRcrltnMotUds
      HvacDampr_uTarDrvrMixMotUds: nonqueued-sender-com-spec{data-element=HvacDampr_uTarDrvrMixMotUds/Val, init-value=0}, provided-interface=HvacDampr_uTarDrvrMixMotUds
      HvacDampr_uTarDrvrRcrltnMotUds: nonqueued-sender-com-spec{data-element=HvacDampr_uTarDrvrRcrltnMotUds/Val, init-value=0}, provided-interface=HvacDampr_uTarDrvrRcrltnMotUds
      HvacDampr_uTarModMotUds: nonqueued-sender-com-spec{data-element=HvacDampr_uTarModMotUds/Val, init-value=0}, provided-interface=HvacDampr_uTarModMotUds
      HvacDampr_uTarPassMixMotUds: nonqueued-sender-com-spec{data-element=HvacDampr_uTarPassMixMotUds/Val, init-value=0}, provided-interface=HvacDampr_uTarPassMixMotUds
      HvacDampr_uTarPassRcrltnMotUds: nonqueued-sender-com-spec{data-element=HvacDampr_uTarPassRcrltnMotUds/Val, init-value=0}, provided-interface=HvacDampr_uTarPassRcrltnMotUds
      HvacDampr_uTarRcrltnMotUds: nonqueued-sender-com-spec{data-element=HvacDampr_uTarRcrltnMotUds/Val, init-value=0}, provided-interface=HvacDampr_uTarRcrltnMotUds
    109 x require port:
      CabinT_t: nonqueued-receiver-com-spec{data-element=CabinT_t/Val, filter=data-filter-type=ALWAYS, init-value=0}, required-interface=CabinT_t
      CabinT_tRe: nonqueued-receiver-com-spec{data-element=CabinT_tRe/Val, filter=data-filter-type=ALWAYS, init-value=0}, required-interface=CabinT_tRe
      ComRx_u8UMM_UsageModeSt: nonqueued-receiver-com-spec{data-element=ComRx_u8UMM_UsageModeSt/Val, filter=data-filter-type=ALWAYS, init-value=0}, required-interface=ComRx_u8UMM_UsageModeSt
      DTC_CabinTSRCMax: required-interface=DiagnosticMonitor
        required-com-specs:
          GetDTCOfEvent
          GetEventExtendedDataRecordEx
          GetEventFailed
          GetEventFreezeFrameDataEx
          GetEventStatus
          GetEventTested
          GetEventUdsStatus
          GetFaultDetectionCounter
          ResetEventDebounceStatus
          ResetEventStatus
          SetEventStatus
      DTC_CabinTSRCMin: required-interface=DiagnosticMonitor
        required-com-specs:
          GetDTCOfEvent
          GetEventExtendedDataRecordEx
          GetEventFailed
          GetEventFreezeFrameDataEx
          GetEventStatus
          GetEventTested
          GetEventUdsStatus
          GetFaultDetectionCounter
          ResetEventDebounceStatus
          ResetEventStatus
          SetEventStatus
      DTC_DrvrMixDamprMotMaxErr: required-interface=DiagnosticMonitor
        required-com-specs:
          GetDTCOfEvent
          GetEventExtendedDataRecordEx
          GetEventFailed
          GetEventFreezeFrameDataEx
          GetEventStatus
          GetEventTested
          GetEventUdsStatus
          GetFaultDetectionCounter
          ResetEventDebounceStatus
          ResetEventStatus
          SetEventStatus
      DTC_DrvrMixDamprMotMinErr: required-interface=DiagnosticMonitor
        required-com-specs:
          GetDTCOfEvent
          GetEventExtendedDataRecordEx
          GetEventFailed
          GetEventFreezeFrameDataEx
          GetEventStatus
          GetEventTested
          GetEventUdsStatus
          GetFaultDetectionCounter
          ResetEventDebounceStatus
          ResetEventStatus
          SetEventStatus
      DTC_DrvrMixDamprMotStuck: required-interface=DiagnosticMonitor
        required-com-specs:
          GetDTCOfEvent
          GetEventExtendedDataRecordEx
          GetEventFailed
          GetEventFreezeFrameDataEx
          GetEventStatus
          GetEventTested
          GetEventUdsStatus
          GetFaultDetectionCounter
          ResetEventDebounceStatus
          ResetEventStatus
          SetEventStatus
      DTC_EvaprTSRCMax: required-interface=DiagnosticMonitor
        required-com-specs:
          GetDTCOfEvent
          GetEventExtendedDataRecordEx
          GetEventFailed
          GetEventFreezeFrameDataEx
          GetEventStatus
          GetEventTested
          GetEventUdsStatus
          GetFaultDetectionCounter
          ResetEventDebounceStatus
          ResetEventStatus
          SetEventStatus
      DTC_EvaprTSRCMin: required-interface=DiagnosticMonitor
        required-com-specs:
          GetDTCOfEvent
          GetEventExtendedDataRecordEx
          GetEventFailed
          GetEventFreezeFrameDataEx
          GetEventStatus
          GetEventTested
          GetEventUdsStatus
          GetFaultDetectionCounter
          ResetEventDebounceStatus
          ResetEventStatus
          SetEventStatus
      DTC_LeReMirrHeatgMax: required-interface=DiagnosticMonitor
        required-com-specs:
          GetDTCOfEvent
          GetEventExtendedDataRecordEx
          GetEventFailed
          GetEventFreezeFrameDataEx
          GetEventStatus
          GetEventTested
          GetEventUdsStatus
          GetFaultDetectionCounter
          ResetEventDebounceStatus
          ResetEventStatus
          SetEventStatus
      DTC_LeReMirrHeatgMin: required-interface=DiagnosticMonitor
        required-com-specs:
          GetDTCOfEvent
          GetEventExtendedDataRecordEx
          GetEventFailed
          GetEventFreezeFrameDataEx
          GetEventStatus
          GetEventTested
          GetEventUdsStatus
          GetFaultDetectionCounter
          ResetEventDebounceStatus
          ResetEventStatus
          SetEventStatus
      DTC_LeSolarSnsrSRCMax: required-interface=DiagnosticMonitor
        required-com-specs:
          GetDTCOfEvent
          GetEventExtendedDataRecordEx
          GetEventFailed
          GetEventFreezeFrameDataEx
          GetEventStatus
          GetEventTested
          GetEventUdsStatus
          GetFaultDetectionCounter
          ResetEventDebounceStatus
          ResetEventStatus
          SetEventStatus
      DTC_LeSolarSnsrSRCMin: required-interface=DiagnosticMonitor
        required-com-specs:
          GetDTCOfEvent
          GetEventExtendedDataRecordEx
          GetEventFailed
          GetEventFreezeFrameDataEx
          GetEventStatus
          GetEventTested
          GetEventUdsStatus
          GetFaultDetectionCounter
          ResetEventDebounceStatus
          ResetEventStatus
          SetEventStatus
      DTC_ModDamprMotMaxErr: required-interface=DiagnosticMonitor
        required-com-specs:
          GetDTCOfEvent
          GetEventExtendedDataRecordEx
          GetEventFailed
          GetEventFreezeFrameDataEx
          GetEventStatus
          GetEventTested
          GetEventUdsStatus
          GetFaultDetectionCounter
          ResetEventDebounceStatus
          ResetEventStatus
          SetEventStatus
      DTC_ModDamprMotMinErr: required-interface=DiagnosticMonitor
        required-com-specs:
          GetDTCOfEvent
          GetEventExtendedDataRecordEx
          GetEventFailed
          GetEventFreezeFrameDataEx
          GetEventStatus
          GetEventTested
          GetEventUdsStatus
          GetFaultDetectionCounter
          ResetEventDebounceStatus
          ResetEventStatus
          SetEventStatus
      DTC_ModDamprMotStuck: required-interface=DiagnosticMonitor
        required-com-specs:
          GetDTCOfEvent
          GetEventExtendedDataRecordEx
          GetEventFailed
          GetEventFreezeFrameDataEx
          GetEventStatus
          GetEventTested
          GetEventUdsStatus
          GetFaultDetectionCounter
          ResetEventDebounceStatus
          ResetEventStatus
          SetEventStatus
      DTC_PassMixDamprMotMaxErr: required-interface=DiagnosticMonitor
        required-com-specs:
          GetDTCOfEvent
          GetEventExtendedDataRecordEx
          GetEventFailed
          GetEventFreezeFrameDataEx
          GetEventStatus
          GetEventTested
          GetEventUdsStatus
          GetFaultDetectionCounter
          ResetEventDebounceStatus
          ResetEventStatus
          SetEventStatus
      DTC_PassMixDamprMotMinErr: required-interface=DiagnosticMonitor
        required-com-specs:
          GetDTCOfEvent
          GetEventExtendedDataRecordEx
          GetEventFailed
          GetEventFreezeFrameDataEx
          GetEventStatus
          GetEventTested
          GetEventUdsStatus
          GetFaultDetectionCounter
          ResetEventDebounceStatus
          ResetEventStatus
          SetEventStatus
      DTC_PassMixDamprMotStuck: required-interface=DiagnosticMonitor
        required-com-specs:
          GetDTCOfEvent
          GetEventExtendedDataRecordEx
          GetEventFailed
          GetEventFreezeFrameDataEx
          GetEventStatus
          GetEventTested
          GetEventUdsStatus
          GetFaultDetectionCounter
          ResetEventDebounceStatus
          ResetEventStatus
          SetEventStatus
      DTC_RcrltnDamprMotMaxErr: required-interface=DiagnosticMonitor
        required-com-specs:
          GetDTCOfEvent
          GetEventExtendedDataRecordEx
          GetEventFailed
          GetEventFreezeFrameDataEx
          GetEventStatus
          GetEventTested
          GetEventUdsStatus
          GetFaultDetectionCounter
          ResetEventDebounceStatus
          ResetEventStatus
          SetEventStatus
      DTC_RcrltnDamprMotMinErr: required-interface=DiagnosticMonitor
        required-com-specs:
          GetDTCOfEvent
          GetEventExtendedDataRecordEx
          GetEventFailed
          GetEventFreezeFrameDataEx
          GetEventStatus
          GetEventTested
          GetEventUdsStatus
          GetFaultDetectionCounter
          ResetEventDebounceStatus
          ResetEventStatus
          SetEventStatus
      DTC_RcrltnDamprMotStuck: required-interface=DiagnosticMonitor
        required-com-specs:
          GetDTCOfEvent
          GetEventExtendedDataRecordEx
          GetEventFailed
          GetEventFreezeFrameDataEx
          GetEventStatus
          GetEventTested
          GetEventUdsStatus
          GetFaultDetectionCounter
          ResetEventDebounceStatus
          ResetEventStatus
          SetEventStatus
      DTC_ReCabinTSRCMax: required-interface=DiagnosticMonitor
        required-com-specs:
          GetDTCOfEvent
          GetEventExtendedDataRecordEx
          GetEventFailed
          GetEventFreezeFrameDataEx
          GetEventStatus
          GetEventTested
          GetEventUdsStatus
          GetFaultDetectionCounter
          ResetEventDebounceStatus
          ResetEventStatus
          SetEventStatus
      DTC_ReCabinTSRCMin: required-interface=DiagnosticMonitor
        required-com-specs:
          GetDTCOfEvent
          GetEventExtendedDataRecordEx
          GetEventFailed
          GetEventFreezeFrameDataEx
          GetEventStatus
          GetEventTested
          GetEventUdsStatus
          GetFaultDetectionCounter
          ResetEventDebounceStatus
          ResetEventStatus
          SetEventStatus
      DTC_ReEvaprTSRCMax: required-interface=DiagnosticMonitor
        required-com-specs:
          GetDTCOfEvent
          GetEventExtendedDataRecordEx
          GetEventFailed
          GetEventFreezeFrameDataEx
          GetEventStatus
          GetEventTested
          GetEventUdsStatus
          GetFaultDetectionCounter
          ResetEventDebounceStatus
          ResetEventStatus
          SetEventStatus
      DTC_ReEvaprTSRCMin: required-interface=DiagnosticMonitor
        required-com-specs:
          GetDTCOfEvent
          GetEventExtendedDataRecordEx
          GetEventFailed
          GetEventFreezeFrameDataEx
          GetEventStatus
          GetEventTested
          GetEventUdsStatus
          GetFaultDetectionCounter
          ResetEventDebounceStatus
          ResetEventStatus
          SetEventStatus
      DTC_ReWndshdHeatgMax: required-interface=DiagnosticMonitor
        required-com-specs:
          GetDTCOfEvent
          GetEventExtendedDataRecordEx
          GetEventFailed
          GetEventFreezeFrameDataEx
          GetEventStatus
          GetEventTested
          GetEventUdsStatus
          GetFaultDetectionCounter
          ResetEventDebounceStatus
          ResetEventStatus
          SetEventStatus
      DTC_ReWndshdHeatgMin: required-interface=DiagnosticMonitor
        required-com-specs:
          GetDTCOfEvent
          GetEventExtendedDataRecordEx
          GetEventFailed
          GetEventFreezeFrameDataEx
          GetEventStatus
          GetEventTested
          GetEventUdsStatus
          GetFaultDetectionCounter
          ResetEventDebounceStatus
          ResetEventStatus
          SetEventStatus
      DTC_RiReMirrHeatgMax: required-interface=DiagnosticMonitor
        required-com-specs:
          GetDTCOfEvent
          GetEventExtendedDataRecordEx
          GetEventFailed
          GetEventFreezeFrameDataEx
          GetEventStatus
          GetEventTested
          GetEventUdsStatus
          GetFaultDetectionCounter
          ResetEventDebounceStatus
          ResetEventStatus
          SetEventStatus
      DTC_RiReMirrHeatgMin: required-interface=DiagnosticMonitor
        required-com-specs:
          GetDTCOfEvent
          GetEventExtendedDataRecordEx
          GetEventFailed
          GetEventFreezeFrameDataEx
          GetEventStatus
          GetEventTested
          GetEventUdsStatus
          GetFaultDetectionCounter
          ResetEventDebounceStatus
          ResetEventStatus
          SetEventStatus
      DTC_RiSolarSnsrSRCMax: required-interface=DiagnosticMonitor
        required-com-specs:
          GetDTCOfEvent
          GetEventExtendedDataRecordEx
          GetEventFailed
          GetEventFreezeFrameDataEx
          GetEventStatus
          GetEventTested
          GetEventUdsStatus
          GetFaultDetectionCounter
          ResetEventDebounceStatus
          ResetEventStatus
          SetEventStatus
      DTC_RiSolarSnsrSRCMin: required-interface=DiagnosticMonitor
        required-com-specs:
          GetDTCOfEvent
          GetEventExtendedDataRecordEx
          GetEventFailed
          GetEventFreezeFrameDataEx
          GetEventStatus
          GetEventTested
          GetEventUdsStatus
          GetFaultDetectionCounter
          ResetEventDebounceStatus
          ResetEventStatus
          SetEventStatus
      EvaprT_t: nonqueued-receiver-com-spec{data-element=EvaprT_t/Val, filter=data-filter-type=ALWAYS, init-value=0}, required-interface=EvaprT_t
      EvaprT_tRe: nonqueued-receiver-com-spec{data-element=EvaprT_tRe/Val, filter=data-filter-type=ALWAYS, init-value=0}, required-interface=EvaprT_tRe
      gASI_bCCULostCommon: nonqueued-receiver-com-spec{data-element=gASI_bCCULostCommon/Val, filter=data-filter-type=ALWAYS, init-value=0}, required-interface=gASI_bCCULostCommon
      gCFG_bCabinTSnsrAvl: nonqueued-receiver-com-spec{data-element=gCFG_bCabinTSnsrAvl/Val, filter=data-filter-type=ALWAYS, init-value=0}, required-interface=gCFG_bCabinTSnsrAvl
      gCFG_bReCabinTSnsrAvl: nonqueued-receiver-com-spec{data-element=gCFG_bReCabinTSnsrAvl/Val, filter=data-filter-type=ALWAYS, init-value=0}, required-interface=gCFG_bReCabinTSnsrAvl
      gCFG_u8AirVentTSnsrTyp: nonqueued-receiver-com-spec{data-element=gCFG_u8AirVentTSnsrTyp/Val, filter=data-filter-type=ALWAYS, init-value=0}, required-interface=gCFG_u8AirVentTSnsrTyp
      gCFG_u8BlowrCtrlFreqTyp: nonqueued-receiver-com-spec{data-element=gCFG_u8BlowrCtrlFreqTyp/Val, filter=data-filter-type=ALWAYS, init-value=0}, required-interface=gCFG_u8BlowrCtrlFreqTyp
      gCFG_u8BlowrCtrlTyp: nonqueued-receiver-com-spec{data-element=gCFG_u8BlowrCtrlTyp/Val, filter=data-filter-type=ALWAYS, init-value=0}, required-interface=gCFG_u8BlowrCtrlTyp
      gCFG_u8ReBlowrCtrlFreqTyp: nonqueued-receiver-com-spec{data-element=gCFG_u8ReBlowrCtrlFreqTyp/Val, filter=data-filter-type=ALWAYS, init-value=0}, required-interface=gCFG_u8ReBlowrCtrlFreqTyp
      gCFG_u8ReBlowrCtrlTyp: nonqueued-receiver-com-spec{data-element=gCFG_u8ReBlowrCtrlTyp/Val, filter=data-filter-type=ALWAYS, init-value=0}, required-interface=gCFG_u8ReBlowrCtrlTyp
      gCFG_u8ReHVACBoxTyp: nonqueued-receiver-com-spec{data-element=gCFG_u8ReHVACBoxTyp/Val, filter=data-filter-type=ALWAYS, init-value=0}, required-interface=gCFG_u8ReHVACBoxTyp
      gPRM_bHotpumpCfg: nonqueued-receiver-com-spec{data-element=gPRM_bHotpumpCfg/Val, filter=data-filter-type=ALWAYS, init-value=0}, required-interface=gPRM_bHotpumpCfg
      gPRM_bSolarSnsrvalidPrm: nonqueued-receiver-com-spec{data-element=gPRM_bSolarSnsrvalidPrm/Val, filter=data-filter-type=ALWAYS, init-value=0}, required-interface=gPRM_bSolarSnsrvalidPrm
      gPRM_u8AirConditionBoxSpecCfg: nonqueued-receiver-com-spec{data-element=gPRM_u8AirConditionBoxSpecCfg/Val, filter=data-filter-type=ALWAYS, init-value=0}, required-interface=gPRM_u8AirConditionBoxSpecCfg
      gPRM_u8ReAirConditionBoxSpecCfg: nonqueued-receiver-com-spec{data-element=gPRM_u8ReAirConditionBoxSpecCfg/Val, filter=data-filter-type=ALWAYS, init-value=0}, required-interface=gPRM_u8ReAirConditionBoxSpecCfg
      gPRM_u8VehicleTypeCfg: nonqueued-receiver-com-spec{data-element=gPRM_u8VehicleTypeCfg/Val, filter=data-filter-type=ALWAYS, init-value=0}, required-interface=gPRM_u8VehicleTypeCfg
      HvacBlowr_bLPMBlowrEna: nonqueued-receiver-com-spec{data-element=HvacBlowr_bLPMBlowrEna/Val, filter=data-filter-type=ALWAYS, init-value=0}, required-interface=HvacBlowr_bLPMBlowrEna
      HvacBlowr_bReLPMBlowrEna: nonqueued-receiver-com-spec{data-element=HvacBlowr_bReLPMBlowrEna/Val, filter=data-filter-type=ALWAYS, init-value=0}, required-interface=HvacBlowr_bReLPMBlowrEna
      HvacBlowr_freqPWMBlowr: nonqueued-receiver-com-spec{data-element=HvacBlowr_freqPWMBlowr/Val, filter=data-filter-type=ALWAYS, init-value=0}, required-interface=HvacBlowr_freqPWMBlowr
      HvacBlowr_freqRePWMBlowr: nonqueued-receiver-com-spec{data-element=HvacBlowr_freqRePWMBlowr/Val, filter=data-filter-type=ALWAYS, init-value=0}, required-interface=HvacBlowr_freqRePWMBlowr
      HvacBlowr_ratLPMBlowr: nonqueued-receiver-com-spec{data-element=HvacBlowr_ratLPMBlowr/Val, filter=data-filter-type=ALWAYS, init-value=0}, required-interface=HvacBlowr_ratLPMBlowr
      HvacBlowr_ratPWMBlowr: nonqueued-receiver-com-spec{data-element=HvacBlowr_ratPWMBlowr/Val, filter=data-filter-type=ALWAYS, init-value=0}, required-interface=HvacBlowr_ratPWMBlowr
      HvacBlowr_ratReLPMBlowr: nonqueued-receiver-com-spec{data-element=HvacBlowr_ratReLPMBlowr/Val, filter=data-filter-type=ALWAYS, init-value=0}, required-interface=HvacBlowr_ratReLPMBlowr
      HvacBlowr_ratRePWMBlowr: nonqueued-receiver-com-spec{data-element=HvacBlowr_ratRePWMBlowr/Val, filter=data-filter-type=ALWAYS, init-value=0}, required-interface=HvacBlowr_ratRePWMBlowr
      HvacBlowr_stReWindExitSpdLvlAct: nonqueued-receiver-com-spec{data-element=HvacBlowr_stReWindExitSpdLvlAct/Val, filter=data-filter-type=ALWAYS, init-value=0}, required-interface=HvacBlowr_stReWindExitSpdLvlAct
      HvacBlowr_stWindExitSpdLvlAct: nonqueued-receiver-com-spec{data-element=HvacBlowr_stWindExitSpdLvlAct/Val, filter=data-filter-type=ALWAYS, init-value=0}, required-interface=HvacBlowr_stWindExitSpdLvlAct
      HvacBlowr_uRawLPMFb: nonqueued-receiver-com-spec{data-element=HvacBlowr_uRawLPMFb/Val, filter=data-filter-type=ALWAYS, init-value=0}, required-interface=HvacBlowr_uRawLPMFb
      HvacDampr_stDrvrMixMotAct: nonqueued-receiver-com-spec{data-element=HvacDampr_stDrvrMixMotAct/Val, filter=data-filter-type=ALWAYS, init-value=0}, required-interface=HvacDampr_stDrvrMixMotAct
      HvacDampr_stDrvrMixMotDir: nonqueued-receiver-com-spec{data-element=HvacDampr_stDrvrMixMotDir/Val, filter=data-filter-type=ALWAYS, init-value=0}, required-interface=HvacDampr_stDrvrMixMotDir
      HvacDampr_stDrvrMixMotFlt: nonqueued-receiver-com-spec{data-element=HvacDampr_stDrvrMixMotFlt/Val, filter=data-filter-type=ALWAYS, init-value=0}, required-interface=HvacDampr_stDrvrMixMotFlt
      HvacDampr_stDrvrMixMotRunng: nonqueued-receiver-com-spec{data-element=HvacDampr_stDrvrMixMotRunng/Val, filter=data-filter-type=ALWAYS, init-value=0}, required-interface=HvacDampr_stDrvrMixMotRunng
      HvacDampr_stDrvrRcrltnMotAct: nonqueued-receiver-com-spec{data-element=HvacDampr_stDrvrRcrltnMotAct/Val, filter=data-filter-type=ALWAYS, init-value=0}, required-interface=HvacDampr_stDrvrRcrltnMotAct
      HvacDampr_stDrvrRcrltnMotDir: nonqueued-receiver-com-spec{data-element=HvacDampr_stDrvrRcrltnMotDir/Val, filter=data-filter-type=ALWAYS, init-value=0}, required-interface=HvacDampr_stDrvrRcrltnMotDir
      HvacDampr_stDrvrRcrltnMotFlt: nonqueued-receiver-com-spec{data-element=HvacDampr_stDrvrRcrltnMotFlt/Val, filter=data-filter-type=ALWAYS, init-value=0}, required-interface=HvacDampr_stDrvrRcrltnMotFlt
      HvacDampr_stDrvrRcrltnMotRunng: nonqueued-receiver-com-spec{data-element=HvacDampr_stDrvrRcrltnMotRunng/Val, filter=data-filter-type=ALWAYS, init-value=0}, required-interface=HvacDampr_stDrvrRcrltnMotRunng
      HvacDampr_stModMotAct: nonqueued-receiver-com-spec{data-element=HvacDampr_stModMotAct/Val, filter=data-filter-type=ALWAYS, init-value=0}, required-interface=HvacDampr_stModMotAct
      HvacDampr_stModMotDir: nonqueued-receiver-com-spec{data-element=HvacDampr_stModMotDir/Val, filter=data-filter-type=ALWAYS, init-value=0}, required-interface=HvacDampr_stModMotDir
      HvacDampr_stModMotFlt: nonqueued-receiver-com-spec{data-element=HvacDampr_stModMotFlt/Val, filter=data-filter-type=ALWAYS, init-value=0}, required-interface=HvacDampr_stModMotFlt
      HvacDampr_stModMotRunng: nonqueued-receiver-com-spec{data-element=HvacDampr_stModMotRunng/Val, filter=data-filter-type=ALWAYS, init-value=0}, required-interface=HvacDampr_stModMotRunng
      HvacDampr_stPassMixMotAct: nonqueued-receiver-com-spec{data-element=HvacDampr_stPassMixMotAct/Val, filter=data-filter-type=ALWAYS, init-value=0}, required-interface=HvacDampr_stPassMixMotAct
      HvacDampr_stPassMixMotDir: nonqueued-receiver-com-spec{data-element=HvacDampr_stPassMixMotDir/Val, filter=data-filter-type=ALWAYS, init-value=0}, required-interface=HvacDampr_stPassMixMotDir
      HvacDampr_stPassMixMotFlt: nonqueued-receiver-com-spec{data-element=HvacDampr_stPassMixMotFlt/Val, filter=data-filter-type=ALWAYS, init-value=0}, required-interface=HvacDampr_stPassMixMotFlt
      HvacDampr_stPassMixMotRunng: nonqueued-receiver-com-spec{data-element=HvacDampr_stPassMixMotRunng/Val, filter=data-filter-type=ALWAYS, init-value=0}, required-interface=HvacDampr_stPassMixMotRunng
      HvacDampr_stPassRcrltnMotAct: nonqueued-receiver-com-spec{data-element=HvacDampr_stPassRcrltnMotAct/Val, filter=data-filter-type=ALWAYS, init-value=0}, required-interface=HvacDampr_stPassRcrltnMotAct
      HvacDampr_stPassRcrltnMotDir: nonqueued-receiver-com-spec{data-element=HvacDampr_stPassRcrltnMotDir/Val, filter=data-filter-type=ALWAYS, init-value=0}, required-interface=HvacDampr_stPassRcrltnMotDir
      HvacDampr_stPassRcrltnMotFlt: nonqueued-receiver-com-spec{data-element=HvacDampr_stPassRcrltnMotFlt/Val, filter=data-filter-type=ALWAYS, init-value=0}, required-interface=HvacDampr_stPassRcrltnMotFlt
      HvacDampr_stPassRcrltnMotRunng: nonqueued-receiver-com-spec{data-element=HvacDampr_stPassRcrltnMotRunng/Val, filter=data-filter-type=ALWAYS, init-value=0}, required-interface=HvacDampr_stPassRcrltnMotRunng
      HvacDampr_stRcrltnMotAct: nonqueued-receiver-com-spec{data-element=HvacDampr_stRcrltnMotAct/Val, filter=data-filter-type=ALWAYS, init-value=0}, required-interface=HvacDampr_stRcrltnMotAct
      HvacDampr_stRcrltnMotDir: nonqueued-receiver-com-spec{data-element=HvacDampr_stRcrltnMotDir/Val, filter=data-filter-type=ALWAYS, init-value=0}, required-interface=HvacDampr_stRcrltnMotDir
      HvacDampr_stRcrltnMotFlt: nonqueued-receiver-com-spec{data-element=HvacDampr_stRcrltnMotFlt/Val, filter=data-filter-type=ALWAYS, init-value=0}, required-interface=HvacDampr_stRcrltnMotFlt
      HvacDampr_stRcrltnMotRunng: nonqueued-receiver-com-spec{data-element=HvacDampr_stRcrltnMotRunng/Val, filter=data-filter-type=ALWAYS, init-value=0}, required-interface=HvacDampr_stRcrltnMotRunng
      HvacDampr_stReMixMotAct: nonqueued-receiver-com-spec{data-element=HvacDampr_stReMixMotAct/Val, filter=data-filter-type=ALWAYS, init-value=0}, required-interface=HvacDampr_stReMixMotAct
      HvacDampr_stReMixMotDir: nonqueued-receiver-com-spec{data-element=HvacDampr_stReMixMotDir/Val, filter=data-filter-type=ALWAYS, init-value=0}, required-interface=HvacDampr_stReMixMotDir
      HvacDampr_stReMixMotFlt: nonqueued-receiver-com-spec{data-element=HvacDampr_stReMixMotFlt/Val, filter=data-filter-type=ALWAYS, init-value=0}, required-interface=HvacDampr_stReMixMotFlt
      HvacDampr_stReMixMotRunng: nonqueued-receiver-com-spec{data-element=HvacDampr_stReMixMotRunng/Val, filter=data-filter-type=ALWAYS, init-value=0}, required-interface=HvacDampr_stReMixMotRunng
      HvacDampr_stReModMotAct: nonqueued-receiver-com-spec{data-element=HvacDampr_stReModMotAct/Val, filter=data-filter-type=ALWAYS, init-value=0}, required-interface=HvacDampr_stReModMotAct
      HvacDampr_stReModMotDir: nonqueued-receiver-com-spec{data-element=HvacDampr_stReModMotDir/Val, filter=data-filter-type=ALWAYS, init-value=0}, required-interface=HvacDampr_stReModMotDir
      HvacDampr_stReModMotFlt: nonqueued-receiver-com-spec{data-element=HvacDampr_stReModMotFlt/Val, filter=data-filter-type=ALWAYS, init-value=0}, required-interface=HvacDampr_stReModMotFlt
      HvacDampr_stReModMotRunng: nonqueued-receiver-com-spec{data-element=HvacDampr_stReModMotRunng/Val, filter=data-filter-type=ALWAYS, init-value=0}, required-interface=HvacDampr_stReModMotRunng
      HvacDampr_uDrvrMixMotFb: nonqueued-receiver-com-spec{data-element=HvacDampr_uDrvrMixMotFb/Val, filter=data-filter-type=ALWAYS, init-value=0}, required-interface=HvacDampr_uDrvrMixMotFb
      HvacDampr_uDrvrRcrltnMotFb: nonqueued-receiver-com-spec{data-element=HvacDampr_uDrvrRcrltnMotFb/Val, filter=data-filter-type=ALWAYS, init-value=0}, required-interface=HvacDampr_uDrvrRcrltnMotFb
      HvacDampr_uModMotFb: nonqueued-receiver-com-spec{data-element=HvacDampr_uModMotFb/Val, filter=data-filter-type=ALWAYS, init-value=0}, required-interface=HvacDampr_uModMotFb
      HvacDampr_uPassMixMotFb: nonqueued-receiver-com-spec{data-element=HvacDampr_uPassMixMotFb/Val, filter=data-filter-type=ALWAYS, init-value=0}, required-interface=HvacDampr_uPassMixMotFb
      HvacDampr_uPassRcrltnMotFb: nonqueued-receiver-com-spec{data-element=HvacDampr_uPassRcrltnMotFb/Val, filter=data-filter-type=ALWAYS, init-value=0}, required-interface=HvacDampr_uPassRcrltnMotFb
      HvacDampr_uRcrltnMotFb: nonqueued-receiver-com-spec{data-element=HvacDampr_uRcrltnMotFb/Val, filter=data-filter-type=ALWAYS, init-value=0}, required-interface=HvacDampr_uRcrltnMotFb
      HvacDampr_uReMixMotFb: nonqueued-receiver-com-spec{data-element=HvacDampr_uReMixMotFb/Val, filter=data-filter-type=ALWAYS, init-value=0}, required-interface=HvacDampr_uReMixMotFb
      HvacDampr_uReModMotFb: nonqueued-receiver-com-spec{data-element=HvacDampr_uReModMotFb/Val, filter=data-filter-type=ALWAYS, init-value=0}, required-interface=HvacDampr_uReModMotFb
      HvacVentT_tDrvrFaceVent: nonqueued-receiver-com-spec{data-element=HvacVentT_tDrvrFaceVent/Val, filter=data-filter-type=ALWAYS, init-value=0}, required-interface=HvacVentT_tDrvrFaceVent
      HvacVentT_tDrvrFootVent: nonqueued-receiver-com-spec{data-element=HvacVentT_tDrvrFootVent/Val, filter=data-filter-type=ALWAYS, init-value=0}, required-interface=HvacVentT_tDrvrFootVent
      HvacVentT_tPassFaceVent: nonqueued-receiver-com-spec{data-element=HvacVentT_tPassFaceVent/Val, filter=data-filter-type=ALWAYS, init-value=0}, required-interface=HvacVentT_tPassFaceVent
      HvacVentT_tPassFootVent: nonqueued-receiver-com-spec{data-element=HvacVentT_tPassFootVent/Val, filter=data-filter-type=ALWAYS, init-value=0}, required-interface=HvacVentT_tPassFootVent
      ReMirrHeatg_stPsLe: nonqueued-receiver-com-spec{data-element=ReMirrHeatg_stPsLe/Val, filter=data-filter-type=ALWAYS, init-value=0}, required-interface=ReMirrHeatg_stPsLe
      ReMirrHeatg_stPsRi: nonqueued-receiver-com-spec{data-element=ReMirrHeatg_stPsRi/Val, filter=data-filter-type=ALWAYS, init-value=0}, required-interface=ReMirrHeatg_stPsRi
      SolarSnsr_riLe: nonqueued-receiver-com-spec{data-element=SolarSnsr_riLe/Val, filter=data-filter-type=ALWAYS, init-value=0}, required-interface=SolarSnsr_riLe
      SolarSnsr_riRi: nonqueued-receiver-com-spec{data-element=SolarSnsr_riRi/Val, filter=data-filter-type=ALWAYS, init-value=0}, required-interface=SolarSnsr_riRi
      WndshdHeatg_stPsRe: nonqueued-receiver-com-spec{data-element=WndshdHeatg_stPsRe/Val, filter=data-filter-type=ALWAYS, init-value=0}, required-interface=WndshdHeatg_stPsRe
    behavior HVAC_ComCnvTx_InternalBehavior: data-type-mapping=DTMS_HVAC_ComCnvTx
      timing event TMT_HVAC_ComCnvTx_Proc_10ms: start-on-event=HVAC_ComCnvTx_Runnable_10ms, period=0.01
      init event HVAC_ComCnvTx_Runnable_InitEvent: start-on-event=HVAC_ComCnvTx_Runnable_Init
      runnable HVAC_ComCnvTx_Runnable_10ms
        data-receive-point-by-arguments:
          79 x access:
            IN_ComRx_u8UMM_UsageModeSt_Val: accessed-variable=ComRx_u8UMM_UsageModeSt.Val
            IN_gASI_bCCULostCommon_Val: accessed-variable=gASI_bCCULostCommon.Val
            IN_gCFG_bCabinTSnsrAvl_Val: accessed-variable=gCFG_bCabinTSnsrAvl.Val
            IN_gCFG_bReCabinTSnsrAvl_Val: accessed-variable=gCFG_bReCabinTSnsrAvl.Val
            IN_gCFG_u8AirVentTSnsrTyp_Val: accessed-variable=gCFG_u8AirVentTSnsrTyp.Val
            IN_gCFG_u8BlowrCtrlFreqTyp_Val: accessed-variable=gCFG_u8BlowrCtrlFreqTyp.Val
            IN_gCFG_u8BlowrCtrlTyp_Val: accessed-variable=gCFG_u8BlowrCtrlTyp.Val
            IN_gCFG_u8ReBlowrCtrlFreqTyp_Val: accessed-variable=gCFG_u8ReBlowrCtrlFreqTyp.Val
            IN_gCFG_u8ReBlowrCtrlTyp_Val: accessed-variable=gCFG_u8ReBlowrCtrlTyp.Val
            IN_gCFG_u8ReHVACBoxTyp_Val: accessed-variable=gCFG_u8ReHVACBoxTyp.Val
            IN_gPRM_bHotpumpCfg_Val: accessed-variable=gPRM_bHotpumpCfg.Val
            IN_gPRM_bSolarSnsrvalidPrm_Val: accessed-variable=gPRM_bSolarSnsrvalidPrm.Val
            IN_gPRM_u8AirConditionBoxSpecCfg_Val: accessed-variable=gPRM_u8AirConditionBoxSpecCfg.Val
            IN_gPRM_u8ReAirConditionBoxSpecCfg_Val: accessed-variable=gPRM_u8ReAirConditionBoxSpecCfg.Val
            IN_gPRM_u8VehicleTypeCfg_Val: accessed-variable=gPRM_u8VehicleTypeCfg.Val
            IN_HvacBlowr_bLPMBlowrEna_Val: accessed-variable=HvacBlowr_bLPMBlowrEna.Val
            IN_HvacBlowr_bReLPMBlowrEna_Val: accessed-variable=HvacBlowr_bReLPMBlowrEna.Val
            IN_HvacBlowr_freqPWMBlowr_Val: accessed-variable=HvacBlowr_freqPWMBlowr.Val
            IN_HvacBlowr_freqRePWMBlowr_Val: accessed-variable=HvacBlowr_freqRePWMBlowr.Val
            IN_HvacBlowr_ratLPMBlowr_Val: accessed-variable=HvacBlowr_ratLPMBlowr.Val
            IN_HvacBlowr_ratPWMBlowr_Val: accessed-variable=HvacBlowr_ratPWMBlowr.Val
            IN_HvacBlowr_ratReLPMBlowr_Val: accessed-variable=HvacBlowr_ratReLPMBlowr.Val
            IN_HvacBlowr_ratRePWMBlowr_Val: accessed-variable=HvacBlowr_ratRePWMBlowr.Val
            IN_HvacBlowr_stReWindExitSpdLvlAct_Val: accessed-variable=HvacBlowr_stReWindExitSpdLvlAct.Val
            IN_HvacBlowr_stWindExitSpdLvlAct_Val: accessed-variable=HvacBlowr_stWindExitSpdLvlAct.Val
            IN_HvacBlowr_uRawLPMFb_Val: accessed-variable=HvacBlowr_uRawLPMFb.Val
            IN_HvacDampr_stDrvrMixMotAct_Val: accessed-variable=HvacDampr_stDrvrMixMotAct.Val
            IN_HvacDampr_stDrvrMixMotDir_Val: accessed-variable=HvacDampr_stDrvrMixMotDir.Val
            IN_HvacDampr_stDrvrMixMotFlt_Val: accessed-variable=HvacDampr_stDrvrMixMotFlt.Val
            IN_HvacDampr_stDrvrMixMotRunng_Val: accessed-variable=HvacDampr_stDrvrMixMotRunng.Val
            IN_HvacDampr_stDrvrRcrltnMotAct_Val: accessed-variable=HvacDampr_stDrvrRcrltnMotAct.Val
            IN_HvacDampr_stDrvrRcrltnMotDir_Val: accessed-variable=HvacDampr_stDrvrRcrltnMotDir.Val
            IN_HvacDampr_stDrvrRcrltnMotFlt_Val: accessed-variable=HvacDampr_stDrvrRcrltnMotFlt.Val
            IN_HvacDampr_stDrvrRcrltnMotRunng_Val: accessed-variable=HvacDampr_stDrvrRcrltnMotRunng.Val
            IN_HvacDampr_stModMotAct_Val: accessed-variable=HvacDampr_stModMotAct.Val
            IN_HvacDampr_stModMotDir_Val: accessed-variable=HvacDampr_stModMotDir.Val
            IN_HvacDampr_stModMotFlt_Val: accessed-variable=HvacDampr_stModMotFlt.Val
            IN_HvacDampr_stModMotRunng_Val: accessed-variable=HvacDampr_stModMotRunng.Val
            IN_HvacDampr_stPassMixMotAct_Val: accessed-variable=HvacDampr_stPassMixMotAct.Val
            IN_HvacDampr_stPassMixMotDir_Val: accessed-variable=HvacDampr_stPassMixMotDir.Val
            IN_HvacDampr_stPassMixMotFlt_Val: accessed-variable=HvacDampr_stPassMixMotFlt.Val
            IN_HvacDampr_stPassMixMotRunng_Val: accessed-variable=HvacDampr_stPassMixMotRunng.Val
            IN_HvacDampr_stPassRcrltnMotAct_Val: accessed-variable=HvacDampr_stPassRcrltnMotAct.Val
            IN_HvacDampr_stPassRcrltnMotDir_Val: accessed-variable=HvacDampr_stPassRcrltnMotDir.Val
            IN_HvacDampr_stPassRcrltnMotFlt_Val: accessed-variable=HvacDampr_stPassRcrltnMotFlt.Val
            IN_HvacDampr_stPassRcrltnMotRunng_Val: accessed-variable=HvacDampr_stPassRcrltnMotRunng.Val
            IN_HvacDampr_stRcrltnMotAct_Val: accessed-variable=HvacDampr_stRcrltnMotAct.Val
            IN_HvacDampr_stRcrltnMotDir_Val: accessed-variable=HvacDampr_stRcrltnMotDir.Val
            IN_HvacDampr_stRcrltnMotFlt_Val: accessed-variable=HvacDampr_stRcrltnMotFlt.Val
            IN_HvacDampr_stRcrltnMotRunng_Val: accessed-variable=HvacDampr_stRcrltnMotRunng.Val
            IN_HvacDampr_stReMixMotAct_Val: accessed-variable=HvacDampr_stReMixMotAct.Val
            IN_HvacDampr_stReMixMotDir_Val: accessed-variable=HvacDampr_stReMixMotDir.Val
            IN_HvacDampr_stReMixMotFlt_Val: accessed-variable=HvacDampr_stReMixMotFlt.Val
            IN_HvacDampr_stReMixMotRunng_Val: accessed-variable=HvacDampr_stReMixMotRunng.Val
            IN_HvacDampr_stReModMotAct_Val: accessed-variable=HvacDampr_stReModMotAct.Val
            IN_HvacDampr_stReModMotDir_Val: accessed-variable=HvacDampr_stReModMotDir.Val
            IN_HvacDampr_stReModMotFlt_Val: accessed-variable=HvacDampr_stReModMotFlt.Val
            IN_HvacDampr_stReModMotRunng_Val: accessed-variable=HvacDampr_stReModMotRunng.Val
            IN_HvacDampr_uDrvrMixMotFb_Val: accessed-variable=HvacDampr_uDrvrMixMotFb.Val
            IN_HvacDampr_uDrvrRcrltnMotFb_Val: accessed-variable=HvacDampr_uDrvrRcrltnMotFb.Val
            IN_HvacDampr_uModMotFb_Val: accessed-variable=HvacDampr_uModMotFb.Val
            IN_HvacDampr_uPassMixMotFb_Val: accessed-variable=HvacDampr_uPassMixMotFb.Val
            IN_HvacDampr_uPassRcrltnMotFb_Val: accessed-variable=HvacDampr_uPassRcrltnMotFb.Val
            IN_HvacDampr_uRcrltnMotFb_Val: accessed-variable=HvacDampr_uRcrltnMotFb.Val
            IN_HvacDampr_uReMixMotFb_Val: accessed-variable=HvacDampr_uReMixMotFb.Val
            IN_HvacDampr_uReModMotFb_Val: accessed-variable=HvacDampr_uReModMotFb.Val
            IN_ReMirrHeatg_stPsLe_Val: accessed-variable=ReMirrHeatg_stPsLe.Val
            IN_ReMirrHeatg_stPsRi_Val: accessed-variable=ReMirrHeatg_stPsRi.Val
            IN_SolarSnsr_riLe_Val: accessed-variable=SolarSnsr_riLe.Val
            IN_SolarSnsr_riRi_Val: accessed-variable=SolarSnsr_riRi.Val
            IN_WndshdHeatg_stPsRe_Val: accessed-variable=WndshdHeatg_stPsRe.Val
            REC_CabinT_t_Val: accessed-variable=CabinT_t.Val
            REC_CabinT_tRe_Val: accessed-variable=CabinT_tRe.Val
            REC_EvaprT_t_Val: accessed-variable=EvaprT_t.Val
            REC_EvaprT_tRe_Val: accessed-variable=EvaprT_tRe.Val
            REC_HvacVentT_tDrvrFaceVent_Val: accessed-variable=HvacVentT_tDrvrFaceVent.Val
            REC_HvacVentT_tDrvrFootVent_Val: accessed-variable=HvacVentT_tDrvrFootVent.Val
            REC_HvacVentT_tPassFaceVent_Val: accessed-variable=HvacVentT_tPassFaceVent.Val
            REC_HvacVentT_tPassFootVent_Val: accessed-variable=HvacVentT_tPassFootVent.Val
        data-send-points:
          69 x access:
            OUT_ComTx_bHVAC_LeftExtMirrorHeatActSt_Val: accessed-variable=ComTx_bHVAC_LeftExtMirrorHeatActSt.Val
            OUT_ComTx_bHVAC_ModeServoSt_Val: accessed-variable=ComTx_bHVAC_ModeServoSt.Val
            OUT_ComTx_bHVAC_RearDefrostActSt_Val: accessed-variable=ComTx_bHVAC_RearDefrostActSt.Val
            OUT_ComTx_bHVAC_RightExtMirrorHeatActSt_Val: accessed-variable=ComTx_bHVAC_RightExtMirrorHeatActSt.Val
            OUT_ComTx_bHVAC_RightExtMirrorHeatActSt_Val_1: accessed-variable=ComTx_bHVAC_RightExtMirrorHeatActSt.Val
            OUT_ComTx_bHVAC_RrAMDoorPostionVD_Val: accessed-variable=ComTx_bHVAC_RrAMDoorPostionVD.Val
            OUT_ComTx_bHVAC_RrBlowerPowerSt_Val: accessed-variable=ComTx_bHVAC_RrBlowerPowerSt.Val
            OUT_ComTx_bHVAC_RrModeServoSt_Val: accessed-variable=ComTx_bHVAC_RrModeServoSt.Val
            OUT_ComTx_u16HVAC_DrFaceOutletTemp_Val: accessed-variable=ComTx_u16HVAC_DrFaceOutletTemp.Val
            OUT_ComTx_u16HVAC_DrFootOutletTemp_Val: accessed-variable=ComTx_u16HVAC_DrFootOutletTemp.Val
            OUT_ComTx_u16HVAC_PaFaceOutletTemp_Val: accessed-variable=ComTx_u16HVAC_PaFaceOutletTemp.Val
            OUT_ComTx_u16HVAC_PaFootOutletTemp_Val: accessed-variable=ComTx_u16HVAC_PaFootOutletTemp.Val
            OUT_ComTx_u16HVAC_RawCabinTemp_Val: accessed-variable=ComTx_u16HVAC_RawCabinTemp.Val
            OUT_ComTx_u16HVAC_RawEvaTemp_Val: accessed-variable=ComTx_u16HVAC_RawEvaTemp.Val
            OUT_ComTx_u16HVAC_RrRawCabinTemp_Val: accessed-variable=ComTx_u16HVAC_RrRawCabinTemp.Val
            OUT_ComTx_u16HVAC_RrRawEvaTemp_Val: accessed-variable=ComTx_u16HVAC_RrRawEvaTemp.Val
            OUT_ComTx_u8HVAC_AirCirculationAct_Val: accessed-variable=ComTx_u8HVAC_AirCirculationAct.Val
            OUT_ComTx_u8HVAC_CirculationServoFault_Val: accessed-variable=ComTx_u8HVAC_CirculationServoFault.Val
            OUT_ComTx_u8HVAC_CirculationServoFB_Val: accessed-variable=ComTx_u8HVAC_CirculationServoFB.Val
            OUT_ComTx_u8HVAC_DrAirCirculationAct_Val: accessed-variable=ComTx_u8HVAC_DrAirCirculationAct.Val
            OUT_ComTx_u8HVAC_DrAirCirculationServoFault_Val: accessed-variable=ComTx_u8HVAC_DrAirCirculationServoFault.Val
            OUT_ComTx_u8HVAC_DrAirCirculationServoFB_Val: accessed-variable=ComTx_u8HVAC_DrAirCirculationServoFB.Val
            OUT_ComTx_u8HVAC_DrAMDoorPostionAct_Val: accessed-variable=ComTx_u8HVAC_DrAMDoorPostionAct.Val
            OUT_ComTx_u8HVAC_DrAMServoFault_Val: accessed-variable=ComTx_u8HVAC_DrAMServoFault.Val
            OUT_ComTx_u8HVAC_DrAMServoFB_Val: accessed-variable=ComTx_u8HVAC_DrAMServoFB.Val
            OUT_ComTx_u8HVAC_DrFaceOutletTempFault_Val: accessed-variable=ComTx_u8HVAC_DrFaceOutletTempFault.Val
            OUT_ComTx_u8HVAC_DrFootOutletTempFault_Val: accessed-variable=ComTx_u8HVAC_DrFootOutletTempFault.Val
            OUT_ComTx_u8HVAC_ModeServoFault_Val: accessed-variable=ComTx_u8HVAC_ModeServoFault.Val
            OUT_ComTx_u8HVAC_ModeServoFB_Val: accessed-variable=ComTx_u8HVAC_ModeServoFB.Val
            OUT_ComTx_u8HVAC_PaAirCirculationAct_Val: accessed-variable=ComTx_u8HVAC_PaAirCirculationAct.Val
            OUT_ComTx_u8HVAC_PaAirCirculationServoFault_Val: accessed-variable=ComTx_u8HVAC_PaAirCirculationServoFault.Val
            OUT_ComTx_u8HVAC_PaAirCirculationServoFB_Val: accessed-variable=ComTx_u8HVAC_PaAirCirculationServoFB.Val
            OUT_ComTx_u8HVAC_PaAMDoorPostionAct_Val: accessed-variable=ComTx_u8HVAC_PaAMDoorPostionAct.Val
            OUT_ComTx_u8HVAC_PaAMServoFault_Val: accessed-variable=ComTx_u8HVAC_PaAMServoFault.Val
            OUT_ComTx_u8HVAC_PaAMServoFB_Val: accessed-variable=ComTx_u8HVAC_PaAMServoFB.Val
            OUT_ComTx_u8HVAC_PaFaceOutletTempFault_Val: accessed-variable=ComTx_u8HVAC_PaFaceOutletTempFault.Val
            OUT_ComTx_u8HVAC_PaFootOutletTempFault_Val: accessed-variable=ComTx_u8HVAC_PaFootOutletTempFault.Val
            OUT_ComTx_u8HVAC_RawCabinTempFault_Val: accessed-variable=ComTx_u8HVAC_RawCabinTempFault.Val
            OUT_ComTx_u8HVAC_RawEvaTempFault_Val: accessed-variable=ComTx_u8HVAC_RawEvaTempFault.Val
            OUT_ComTx_u8HVAC_RrAMDoorPostion_Val: accessed-variable=ComTx_u8HVAC_RrAMDoorPostion.Val
            OUT_ComTx_u8HVAC_RrAMDoorPostionAct_Val: accessed-variable=ComTx_u8HVAC_RrAMDoorPostionAct.Val
            OUT_ComTx_u8HVAC_RrAMServoFault_Val: accessed-variable=ComTx_u8HVAC_RrAMServoFault.Val
            OUT_ComTx_u8HVAC_RrAMServoFB_Val: accessed-variable=ComTx_u8HVAC_RrAMServoFB.Val
            OUT_ComTx_u8HVAC_RrModeServoFault_Val: accessed-variable=ComTx_u8HVAC_RrModeServoFault.Val
            OUT_ComTx_u8HVAC_RrModeServoFB_Val: accessed-variable=ComTx_u8HVAC_RrModeServoFB.Val
            OUT_ComTx_u8HVAC_RrRawCabinTempFault_Val: accessed-variable=ComTx_u8HVAC_RrRawCabinTempFault.Val
            OUT_ComTx_u8HVAC_RrRawEvaTempFault_Val: accessed-variable=ComTx_u8HVAC_RrRawEvaTempFault.Val
            OUT_ComTx_u8HVAC_RrWindExitModeAct_Val: accessed-variable=ComTx_u8HVAC_RrWindExitModeAct.Val
            OUT_ComTx_u8HVAC_RrWindExitSpdLvlAct_Val: accessed-variable=ComTx_u8HVAC_RrWindExitSpdLvlAct.Val
            OUT_ComTx_u8HVAC_SolarValueLeft_Val: accessed-variable=ComTx_u8HVAC_SolarValueLeft.Val
            OUT_ComTx_u8HVAC_SolarValueLeftFault_Val: accessed-variable=ComTx_u8HVAC_SolarValueLeftFault.Val
            OUT_ComTx_u8HVAC_SolarValueRight_Val: accessed-variable=ComTx_u8HVAC_SolarValueRight.Val
            OUT_ComTx_u8HVAC_SolarValueRightFault_Val: accessed-variable=ComTx_u8HVAC_SolarValueRightFault.Val
            OUT_ComTx_u8HVAC_WindExitModeAct_Val: accessed-variable=ComTx_u8HVAC_WindExitModeAct.Val
            OUT_ComTx_u8HVAC_WindExitSpdLvlAct_Val: accessed-variable=ComTx_u8HVAC_WindExitSpdLvlAct.Val
            OUT_HvacBlowr_prcTarFrntBlowrUds_Val: accessed-variable=HvacBlowr_prcTarFrntBlowrUds.Val
            OUT_HvacBlowr_uTarFrntBlowrUds_Val: accessed-variable=HvacBlowr_uTarFrntBlowrUds.Val
            OUT_HvacDampr_uActDrvrRcrltnMotUds_Val: accessed-variable=HvacDampr_uActDrvrRcrltnMotUds.Val
            OUT_HvacDampr_uActModMotUds_Val: accessed-variable=HvacDampr_uActModMotUds.Val
            OUT_HvacDampr_uActPassMixMotUds_Val: accessed-variable=HvacDampr_uActPassMixMotUds.Val
            OUT_HvacDampr_uActPassRcrltnMotUds_Val: accessed-variable=HvacDampr_uActPassRcrltnMotUds.Val
            OUT_HvacDampr_uActPsgrMixMotUds_Val: accessed-variable=HvacDampr_uActPsgrMixMotUds.Val
            OUT_HvacDampr_uActRcrltnMotUds_Val: accessed-variable=HvacDampr_uActRcrltnMotUds.Val
            OUT_HvacDampr_uTarDrvrMixMotUds_Val: accessed-variable=HvacDampr_uTarDrvrMixMotUds.Val
            OUT_HvacDampr_uTarDrvrRcrltnMotUds_Val: accessed-variable=HvacDampr_uTarDrvrRcrltnMotUds.Val
            OUT_HvacDampr_uTarModMotUds_Val: accessed-variable=HvacDampr_uTarModMotUds.Val
            OUT_HvacDampr_uTarPassMixMotUds_Val: accessed-variable=HvacDampr_uTarPassMixMotUds.Val
            OUT_HvacDampr_uTarPassRcrltnMotUds_Val: accessed-variable=HvacDampr_uTarPassRcrltnMotUds.Val
            OUT_HvacDampr_uTarRcrltnMotUds_Val: accessed-variable=HvacDampr_uTarRcrltnMotUds.Val
        60 x sync call, all with timeout=1E-06:
          SC_DTC_CabinTSRCMax_GetEventFailed: operation=DTC_CabinTSRCMax.GetEventFailed
          SC_DTC_CabinTSRCMax_GetEventTested: operation=DTC_CabinTSRCMax.GetEventTested
          SC_DTC_CabinTSRCMin_GetEventFailed: operation=DTC_CabinTSRCMin.GetEventFailed
          SC_DTC_CabinTSRCMin_GetEventTested: operation=DTC_CabinTSRCMin.GetEventTested
          SC_DTC_DrvrMixDamprMotMaxErr_GetEventFailed: operation=DTC_DrvrMixDamprMotMaxErr.GetEventFailed
          SC_DTC_DrvrMixDamprMotMaxErr_GetEventTested: operation=DTC_DrvrMixDamprMotMaxErr.GetEventTested
          SC_DTC_DrvrMixDamprMotMinErr_GetEventFailed: operation=DTC_DrvrMixDamprMotMinErr.GetEventFailed
          SC_DTC_DrvrMixDamprMotMinErr_GetEventTested: operation=DTC_DrvrMixDamprMotMinErr.GetEventTested
          SC_DTC_DrvrMixDamprMotStuck_GetEventFailed: operation=DTC_DrvrMixDamprMotStuck.GetEventFailed
          SC_DTC_DrvrMixDamprMotStuck_GetEventTested: operation=DTC_DrvrMixDamprMotStuck.GetEventTested
          SC_DTC_EvaprTSRCMax_GetEventFailed: operation=DTC_EvaprTSRCMax.GetEventFailed
          SC_DTC_EvaprTSRCMax_GetEventTested: operation=DTC_EvaprTSRCMax.GetEventTested
          SC_DTC_EvaprTSRCMin_GetEventFailed: operation=DTC_EvaprTSRCMin.GetEventFailed
          SC_DTC_EvaprTSRCMin_GetEventTested: operation=DTC_EvaprTSRCMin.GetEventTested
          SC_DTC_LeReMirrHeatgMax_GetEventFailed: operation=DTC_LeReMirrHeatgMax.GetEventFailed
          SC_DTC_LeReMirrHeatgMax_GetEventTested: operation=DTC_LeReMirrHeatgMax.GetEventTested
          SC_DTC_LeReMirrHeatgMin_GetEventFailed: operation=DTC_LeReMirrHeatgMin.GetEventFailed
          SC_DTC_LeReMirrHeatgMin_GetEventTested: operation=DTC_LeReMirrHeatgMin.GetEventTested
          SC_DTC_LeSolarSnsrSRCMax_GetEventFailed: operation=DTC_LeSolarSnsrSRCMax.GetEventFailed
          SC_DTC_LeSolarSnsrSRCMax_GetEventTested: operation=DTC_LeSolarSnsrSRCMax.GetEventTested
          SC_DTC_LeSolarSnsrSRCMin_GetEventFailed: operation=DTC_LeSolarSnsrSRCMin.GetEventFailed
          SC_DTC_LeSolarSnsrSRCMin_GetEventTested: operation=DTC_LeSolarSnsrSRCMin.GetEventTested
          SC_DTC_ModDamprMotMaxErr_GetEventFailed: operation=DTC_ModDamprMotMaxErr.GetEventFailed
          SC_DTC_ModDamprMotMaxErr_GetEventTested: operation=DTC_ModDamprMotMaxErr.GetEventTested
          SC_DTC_ModDamprMotMinErr_GetEventFailed: operation=DTC_ModDamprMotMinErr.GetEventFailed
          SC_DTC_ModDamprMotMinErr_GetEventTested: operation=DTC_ModDamprMotMinErr.GetEventTested
          SC_DTC_ModDamprMotStuck_GetEventFailed: operation=DTC_ModDamprMotStuck.GetEventFailed
          SC_DTC_ModDamprMotStuck_GetEventTested: operation=DTC_ModDamprMotStuck.GetEventTested
          SC_DTC_PassMixDamprMotMaxErr_GetEventFailed: operation=DTC_PassMixDamprMotMaxErr.GetEventFailed
          SC_DTC_PassMixDamprMotMaxErr_GetEventTested: operation=DTC_PassMixDamprMotMaxErr.GetEventTested
          SC_DTC_PassMixDamprMotMinErr_GetEventFailed: operation=DTC_PassMixDamprMotMinErr.GetEventFailed
          SC_DTC_PassMixDamprMotMinErr_GetEventTested: operation=DTC_PassMixDamprMotMinErr.GetEventTested
          SC_DTC_PassMixDamprMotStuck_GetEventFailed: operation=DTC_PassMixDamprMotStuck.GetEventFailed
          SC_DTC_PassMixDamprMotStuck_GetEventTested: operation=DTC_PassMixDamprMotStuck.GetEventTested
          SC_DTC_RcrltnDamprMotMaxErr_GetEventFailed: operation=DTC_RcrltnDamprMotMaxErr.GetEventFailed
          SC_DTC_RcrltnDamprMotMaxErr_GetEventTested: operation=DTC_RcrltnDamprMotMaxErr.GetEventTested
          SC_DTC_RcrltnDamprMotMinErr_GetEventFailed: operation=DTC_RcrltnDamprMotMinErr.GetEventFailed
          SC_DTC_RcrltnDamprMotMinErr_GetEventTested: operation=DTC_RcrltnDamprMotMinErr.GetEventTested
          SC_DTC_RcrltnDamprMotStuck_GetEventFailed: operation=DTC_RcrltnDamprMotStuck.GetEventFailed
          SC_DTC_RcrltnDamprMotStuck_GetEventTested: operation=DTC_RcrltnDamprMotStuck.GetEventTested
          SC_DTC_ReCabinTSRCMax_GetEventFailed: operation=DTC_ReCabinTSRCMax.GetEventFailed
          SC_DTC_ReCabinTSRCMax_GetEventTested: operation=DTC_ReCabinTSRCMax.GetEventTested
          SC_DTC_ReCabinTSRCMin_GetEventFailed: operation=DTC_ReCabinTSRCMin.GetEventFailed
          SC_DTC_ReCabinTSRCMin_GetEventTested: operation=DTC_ReCabinTSRCMin.GetEventTested
          SC_DTC_ReEvaprTSRCMax_GetEventFailed: operation=DTC_ReEvaprTSRCMax.GetEventFailed
          SC_DTC_ReEvaprTSRCMax_GetEventTested: operation=DTC_ReEvaprTSRCMax.GetEventTested
          SC_DTC_ReEvaprTSRCMin_GetEventFailed: operation=DTC_ReEvaprTSRCMin.GetEventFailed
          SC_DTC_ReEvaprTSRCMin_GetEventTested: operation=DTC_ReEvaprTSRCMin.GetEventTested
          SC_DTC_ReWndshdHeatgMax_GetEventFailed: operation=DTC_ReWndshdHeatgMax.GetEventFailed
          SC_DTC_ReWndshdHeatgMax_GetEventTested: operation=DTC_ReWndshdHeatgMax.GetEventTested
          SC_DTC_ReWndshdHeatgMin_GetEventFailed: operation=DTC_ReWndshdHeatgMin.GetEventFailed
          SC_DTC_ReWndshdHeatgMin_GetEventTested: operation=DTC_ReWndshdHeatgMin.GetEventTested
          SC_DTC_RiReMirrHeatgMax_GetEventFailed: operation=DTC_RiReMirrHeatgMax.GetEventFailed
          SC_DTC_RiReMirrHeatgMax_GetEventTested: operation=DTC_RiReMirrHeatgMax.GetEventTested
          SC_DTC_RiReMirrHeatgMin_GetEventFailed: operation=DTC_RiReMirrHeatgMin.GetEventFailed
          SC_DTC_RiReMirrHeatgMin_GetEventTested: operation=DTC_RiReMirrHeatgMin.GetEventTested
          SC_DTC_RiSolarSnsrSRCMax_GetEventFailed: operation=DTC_RiSolarSnsrSRCMax.GetEventFailed
          SC_DTC_RiSolarSnsrSRCMax_GetEventTested: operation=DTC_RiSolarSnsrSRCMax.GetEventTested
          SC_DTC_RiSolarSnsrSRCMin_GetEventFailed: operation=DTC_RiSolarSnsrSRCMin.GetEventFailed
          SC_DTC_RiSolarSnsrSRCMin_GetEventTested: operation=DTC_RiSolarSnsrSRCMin.GetEventTested
      runnable HVAC_ComCnvTx_Runnable_Init
        data-receive-point-by-arguments:
          79 x access:
            REC_CabinT_t_Val: accessed-variable=CabinT_t.Val
            REC_CabinT_tRe_Val: accessed-variable=CabinT_tRe.Val
            REC_ComRx_u8UMM_UsageModeSt_Val: accessed-variable=ComRx_u8UMM_UsageModeSt.Val
            REC_EvaprT_t_Val: accessed-variable=EvaprT_t.Val
            REC_EvaprT_tRe_Val: accessed-variable=EvaprT_tRe.Val
            REC_gASI_bCCULostCommon_Val: accessed-variable=gASI_bCCULostCommon.Val
            REC_gCFG_bCabinTSnsrAvl_Val: accessed-variable=gCFG_bCabinTSnsrAvl.Val
            REC_gCFG_bReCabinTSnsrAvl_Val: accessed-variable=gCFG_bReCabinTSnsrAvl.Val
            REC_gCFG_u8AirVentTSnsrTyp_Val: accessed-variable=gCFG_u8AirVentTSnsrTyp.Val
            REC_gCFG_u8BlowrCtrlFreqTyp_Val: accessed-variable=gCFG_u8BlowrCtrlFreqTyp.Val
            REC_gCFG_u8BlowrCtrlTyp_Val: accessed-variable=gCFG_u8BlowrCtrlTyp.Val
            REC_gCFG_u8ReBlowrCtrlFreqTyp_Val: accessed-variable=gCFG_u8ReBlowrCtrlFreqTyp.Val
            REC_gCFG_u8ReBlowrCtrlTyp_Val: accessed-variable=gCFG_u8ReBlowrCtrlTyp.Val
            REC_gCFG_u8ReHVACBoxTyp_Val: accessed-variable=gCFG_u8ReHVACBoxTyp.Val
            REC_gPRM_bHotpumpCfg_Val: accessed-variable=gPRM_bHotpumpCfg.Val
            REC_gPRM_bSolarSnsrvalidPrm_Val: accessed-variable=gPRM_bSolarSnsrvalidPrm.Val
            REC_gPRM_u8AirConditionBoxSpecCfg_Val: accessed-variable=gPRM_u8AirConditionBoxSpecCfg.Val
            REC_gPRM_u8ReAirConditionBoxSpecCfg_Val: accessed-variable=gPRM_u8ReAirConditionBoxSpecCfg.Val
            REC_gPRM_u8VehicleTypeCfg_Val: accessed-variable=gPRM_u8VehicleTypeCfg.Val
            REC_HvacBlowr_bLPMBlowrEna_Val: accessed-variable=HvacBlowr_bLPMBlowrEna.Val
            REC_HvacBlowr_bReLPMBlowrEna_Val: accessed-variable=HvacBlowr_bReLPMBlowrEna.Val
            REC_HvacBlowr_freqPWMBlowr_Val: accessed-variable=HvacBlowr_freqPWMBlowr.Val
            REC_HvacBlowr_freqRePWMBlowr_Val: accessed-variable=HvacBlowr_freqRePWMBlowr.Val
            REC_HvacBlowr_ratLPMBlowr_Val: accessed-variable=HvacBlowr_ratLPMBlowr.Val
            REC_HvacBlowr_ratPWMBlowr_Val: accessed-variable=HvacBlowr_ratPWMBlowr.Val
            REC_HvacBlowr_ratReLPMBlowr_Val: accessed-variable=HvacBlowr_ratReLPMBlowr.Val
            REC_HvacBlowr_ratRePWMBlowr_Val: accessed-variable=HvacBlowr_ratRePWMBlowr.Val
            REC_HvacBlowr_stReWindExitSpdLvlAct_Val: accessed-variable=HvacBlowr_stReWindExitSpdLvlAct.Val
            REC_HvacBlowr_stWindExitSpdLvlAct_Val: accessed-variable=HvacBlowr_stWindExitSpdLvlAct.Val
            REC_HvacBlowr_uRawLPMFb_Val: accessed-variable=HvacBlowr_uRawLPMFb.Val
            REC_HvacDampr_stDrvrMixMotAct_Val: accessed-variable=HvacDampr_stDrvrMixMotAct.Val
            REC_HvacDampr_stDrvrMixMotDir_Val: accessed-variable=HvacDampr_stDrvrMixMotDir.Val
            REC_HvacDampr_stDrvrMixMotFlt_Val: accessed-variable=HvacDampr_stDrvrMixMotFlt.Val
            REC_HvacDampr_stDrvrMixMotRunng_Val: accessed-variable=HvacDampr_stDrvrMixMotRunng.Val
            REC_HvacDampr_stDrvrRcrltnMotAct_Val: accessed-variable=HvacDampr_stDrvrRcrltnMotAct.Val
            REC_HvacDampr_stDrvrRcrltnMotDir_Val: accessed-variable=HvacDampr_stDrvrRcrltnMotDir.Val
            REC_HvacDampr_stDrvrRcrltnMotFlt_Val: accessed-variable=HvacDampr_stDrvrRcrltnMotFlt.Val
            REC_HvacDampr_stDrvrRcrltnMotRunng_Val: accessed-variable=HvacDampr_stDrvrRcrltnMotRunng.Val
            REC_HvacDampr_stModMotAct_Val: accessed-variable=HvacDampr_stModMotAct.Val
            REC_HvacDampr_stModMotDir_Val: accessed-variable=HvacDampr_stModMotDir.Val
            REC_HvacDampr_stModMotFlt_Val: accessed-variable=HvacDampr_stModMotFlt.Val
            REC_HvacDampr_stModMotRunng_Val: accessed-variable=HvacDampr_stModMotRunng.Val
            REC_HvacDampr_stPassMixMotAct_Val: accessed-variable=HvacDampr_stPassMixMotAct.Val
            REC_HvacDampr_stPassMixMotDir_Val: accessed-variable=HvacDampr_stPassMixMotDir.Val
            REC_HvacDampr_stPassMixMotFlt_Val: accessed-variable=HvacDampr_stPassMixMotFlt.Val
            REC_HvacDampr_stPassMixMotRunng_Val: accessed-variable=HvacDampr_stPassMixMotRunng.Val
            REC_HvacDampr_stPassRcrltnMotAct_Val: accessed-variable=HvacDampr_stPassRcrltnMotAct.Val
            REC_HvacDampr_stPassRcrltnMotDir_Val: accessed-variable=HvacDampr_stPassRcrltnMotDir.Val
            REC_HvacDampr_stPassRcrltnMotFlt_Val: accessed-variable=HvacDampr_stPassRcrltnMotFlt.Val
            REC_HvacDampr_stPassRcrltnMotRunng_Val: accessed-variable=HvacDampr_stPassRcrltnMotRunng.Val
            REC_HvacDampr_stRcrltnMotAct_Val: accessed-variable=HvacDampr_stRcrltnMotAct.Val
            REC_HvacDampr_stRcrltnMotDir_Val: accessed-variable=HvacDampr_stRcrltnMotDir.Val
            REC_HvacDampr_stRcrltnMotFlt_Val: accessed-variable=HvacDampr_stRcrltnMotFlt.Val
            REC_HvacDampr_stRcrltnMotRunng_Val: accessed-variable=HvacDampr_stRcrltnMotRunng.Val
            REC_HvacDampr_stReMixMotAct_Val: accessed-variable=HvacDampr_stReMixMotAct.Val
            REC_HvacDampr_stReMixMotDir_Val: accessed-variable=HvacDampr_stReMixMotDir.Val
            REC_HvacDampr_stReMixMotFlt_Val: accessed-variable=HvacDampr_stReMixMotFlt.Val
            REC_HvacDampr_stReMixMotRunng_Val: accessed-variable=HvacDampr_stReMixMotRunng.Val
            REC_HvacDampr_stReModMotAct_Val: accessed-variable=HvacDampr_stReModMotAct.Val
            REC_HvacDampr_stReModMotDir_Val: accessed-variable=HvacDampr_stReModMotDir.Val
            REC_HvacDampr_stReModMotFlt_Val: accessed-variable=HvacDampr_stReModMotFlt.Val
            REC_HvacDampr_stReModMotRunng_Val: accessed-variable=HvacDampr_stReModMotRunng.Val
            REC_HvacDampr_uDrvrMixMotFb_Val: accessed-variable=HvacDampr_uDrvrMixMotFb.Val
            REC_HvacDampr_uDrvrRcrltnMotFb_Val: accessed-variable=HvacDampr_uDrvrRcrltnMotFb.Val
            REC_HvacDampr_uModMotFb_Val: accessed-variable=HvacDampr_uModMotFb.Val
            REC_HvacDampr_uPassMixMotFb_Val: accessed-variable=HvacDampr_uPassMixMotFb.Val
            REC_HvacDampr_uPassRcrltnMotFb_Val: accessed-variable=HvacDampr_uPassRcrltnMotFb.Val
            REC_HvacDampr_uRcrltnMotFb_Val: accessed-variable=HvacDampr_uRcrltnMotFb.Val
            REC_HvacDampr_uReMixMotFb_Val: accessed-variable=HvacDampr_uReMixMotFb.Val
            REC_HvacDampr_uReModMotFb_Val: accessed-variable=HvacDampr_uReModMotFb.Val
            REC_HvacVentT_tDrvrFaceVent_Val: accessed-variable=HvacVentT_tDrvrFaceVent.Val
            REC_HvacVentT_tDrvrFootVent_Val: accessed-variable=HvacVentT_tDrvrFootVent.Val
            REC_HvacVentT_tPassFaceVent_Val: accessed-variable=HvacVentT_tPassFaceVent.Val
            REC_HvacVentT_tPassFootVent_Val: accessed-variable=HvacVentT_tPassFootVent.Val
            REC_ReMirrHeatg_stPsLe_Val: accessed-variable=ReMirrHeatg_stPsLe.Val
            REC_ReMirrHeatg_stPsRi_Val: accessed-variable=ReMirrHeatg_stPsRi.Val
            REC_SolarSnsr_riLe_Val: accessed-variable=SolarSnsr_riLe.Val
            REC_SolarSnsr_riRi_Val: accessed-variable=SolarSnsr_riRi.Val
            REC_WndshdHeatg_stPsRe_Val: accessed-variable=WndshdHeatg_stPsRe.Val
        data-send-points:
          68 x access:
            SEND_ComTx_bHVAC_LeftExtMirrorHeatActSt_Val: accessed-variable=ComTx_bHVAC_LeftExtMirrorHeatActSt.Val
            SEND_ComTx_bHVAC_ModeServoSt_Val: accessed-variable=ComTx_bHVAC_ModeServoSt.Val
            SEND_ComTx_bHVAC_RearDefrostActSt_Val: accessed-variable=ComTx_bHVAC_RearDefrostActSt.Val
            SEND_ComTx_bHVAC_RightExtMirrorHeatActSt_Val: accessed-variable=ComTx_bHVAC_RightExtMirrorHeatActSt.Val
            SEND_ComTx_bHVAC_RrAMDoorPostionVD_Val: accessed-variable=ComTx_bHVAC_RrAMDoorPostionVD.Val
            SEND_ComTx_bHVAC_RrBlowerPowerSt_Val: accessed-variable=ComTx_bHVAC_RrBlowerPowerSt.Val
            SEND_ComTx_bHVAC_RrModeServoSt_Val: accessed-variable=ComTx_bHVAC_RrModeServoSt.Val
            SEND_ComTx_u16HVAC_DrFaceOutletTemp_Val: accessed-variable=ComTx_u16HVAC_DrFaceOutletTemp.Val
            SEND_ComTx_u16HVAC_DrFootOutletTemp_Val: accessed-variable=ComTx_u16HVAC_DrFootOutletTemp.Val
            SEND_ComTx_u16HVAC_PaFaceOutletTemp_Val: accessed-variable=ComTx_u16HVAC_PaFaceOutletTemp.Val
            SEND_ComTx_u16HVAC_PaFootOutletTemp_Val: accessed-variable=ComTx_u16HVAC_PaFootOutletTemp.Val
            SEND_ComTx_u16HVAC_RawCabinTemp_Val: accessed-variable=ComTx_u16HVAC_RawCabinTemp.Val
            SEND_ComTx_u16HVAC_RawEvaTemp_Val: accessed-variable=ComTx_u16HVAC_RawEvaTemp.Val
            SEND_ComTx_u16HVAC_RrRawCabinTemp_Val: accessed-variable=ComTx_u16HVAC_RrRawCabinTemp.Val
            SEND_ComTx_u16HVAC_RrRawEvaTemp_Val: accessed-variable=ComTx_u16HVAC_RrRawEvaTemp.Val
            SEND_ComTx_u8HVAC_AirCirculationAct_Val: accessed-variable=ComTx_u8HVAC_AirCirculationAct.Val
            SEND_ComTx_u8HVAC_CirculationServoFault_Val: accessed-variable=ComTx_u8HVAC_CirculationServoFault.Val
            SEND_ComTx_u8HVAC_CirculationServoFB_Val: accessed-variable=ComTx_u8HVAC_CirculationServoFB.Val
            SEND_ComTx_u8HVAC_DrAirCirculationAct_Val: accessed-variable=ComTx_u8HVAC_DrAirCirculationAct.Val
            SEND_ComTx_u8HVAC_DrAirCirculationServoFault_Val: accessed-variable=ComTx_u8HVAC_DrAirCirculationServoFault.Val
            SEND_ComTx_u8HVAC_DrAirCirculationServoFB_Val: accessed-variable=ComTx_u8HVAC_DrAirCirculationServoFB.Val
            SEND_ComTx_u8HVAC_DrAMDoorPostionAct_Val: accessed-variable=ComTx_u8HVAC_DrAMDoorPostionAct.Val
            SEND_ComTx_u8HVAC_DrAMServoFault_Val: accessed-variable=ComTx_u8HVAC_DrAMServoFault.Val
            SEND_ComTx_u8HVAC_DrAMServoFB_Val: accessed-variable=ComTx_u8HVAC_DrAMServoFB.Val
            SEND_ComTx_u8HVAC_DrFaceOutletTempFault_Val: accessed-variable=ComTx_u8HVAC_DrFaceOutletTempFault.Val
            SEND_ComTx_u8HVAC_DrFootOutletTempFault_Val: accessed-variable=ComTx_u8HVAC_DrFootOutletTempFault.Val
            SEND_ComTx_u8HVAC_ModeServoFault_Val: accessed-variable=ComTx_u8HVAC_ModeServoFault.Val
            SEND_ComTx_u8HVAC_ModeServoFB_Val: accessed-variable=ComTx_u8HVAC_ModeServoFB.Val
            SEND_ComTx_u8HVAC_PaAirCirculationAct_Val: accessed-variable=ComTx_u8HVAC_PaAirCirculationAct.Val
            SEND_ComTx_u8HVAC_PaAirCirculationServoFault_Val: accessed-variable=ComTx_u8HVAC_PaAirCirculationServoFault.Val
            SEND_ComTx_u8HVAC_PaAirCirculationServoFB_Val: accessed-variable=ComTx_u8HVAC_PaAirCirculationServoFB.Val
            SEND_ComTx_u8HVAC_PaAMDoorPostionAct_Val: accessed-variable=ComTx_u8HVAC_PaAMDoorPostionAct.Val
            SEND_ComTx_u8HVAC_PaAMServoFault_Val: accessed-variable=ComTx_u8HVAC_PaAMServoFault.Val
            SEND_ComTx_u8HVAC_PaAMServoFB_Val: accessed-variable=ComTx_u8HVAC_PaAMServoFB.Val
            SEND_ComTx_u8HVAC_PaFaceOutletTempFault_Val: accessed-variable=ComTx_u8HVAC_PaFaceOutletTempFault.Val
            SEND_ComTx_u8HVAC_PaFootOutletTempFault_Val: accessed-variable=ComTx_u8HVAC_PaFootOutletTempFault.Val
            SEND_ComTx_u8HVAC_RawCabinTempFault_Val: accessed-variable=ComTx_u8HVAC_RawCabinTempFault.Val
            SEND_ComTx_u8HVAC_RawEvaTempFault_Val: accessed-variable=ComTx_u8HVAC_RawEvaTempFault.Val
            SEND_ComTx_u8HVAC_RrAMDoorPostion_Val: accessed-variable=ComTx_u8HVAC_RrAMDoorPostion.Val
            SEND_ComTx_u8HVAC_RrAMDoorPostionAct_Val: accessed-variable=ComTx_u8HVAC_RrAMDoorPostionAct.Val
            SEND_ComTx_u8HVAC_RrAMServoFault_Val: accessed-variable=ComTx_u8HVAC_RrAMServoFault.Val
            SEND_ComTx_u8HVAC_RrAMServoFB_Val: accessed-variable=ComTx_u8HVAC_RrAMServoFB.Val
            SEND_ComTx_u8HVAC_RrModeServoFault_Val: accessed-variable=ComTx_u8HVAC_RrModeServoFault.Val
            SEND_ComTx_u8HVAC_RrModeServoFB_Val: accessed-variable=ComTx_u8HVAC_RrModeServoFB.Val
            SEND_ComTx_u8HVAC_RrRawCabinTempFault_Val: accessed-variable=ComTx_u8HVAC_RrRawCabinTempFault.Val
            SEND_ComTx_u8HVAC_RrRawEvaTempFault_Val: accessed-variable=ComTx_u8HVAC_RrRawEvaTempFault.Val
            SEND_ComTx_u8HVAC_RrWindExitModeAct_Val: accessed-variable=ComTx_u8HVAC_RrWindExitModeAct.Val
            SEND_ComTx_u8HVAC_RrWindExitSpdLvlAct_Val: accessed-variable=ComTx_u8HVAC_RrWindExitSpdLvlAct.Val
            SEND_ComTx_u8HVAC_SolarValueLeft_Val: accessed-variable=ComTx_u8HVAC_SolarValueLeft.Val
            SEND_ComTx_u8HVAC_SolarValueLeftFault_Val: accessed-variable=ComTx_u8HVAC_SolarValueLeftFault.Val
            SEND_ComTx_u8HVAC_SolarValueRight_Val: accessed-variable=ComTx_u8HVAC_SolarValueRight.Val
            SEND_ComTx_u8HVAC_SolarValueRightFault_Val: accessed-variable=ComTx_u8HVAC_SolarValueRightFault.Val
            SEND_ComTx_u8HVAC_WindExitModeAct_Val: accessed-variable=ComTx_u8HVAC_WindExitModeAct.Val
            SEND_ComTx_u8HVAC_WindExitSpdLvlAct_Val: accessed-variable=ComTx_u8HVAC_WindExitSpdLvlAct.Val
            SEND_HvacBlowr_prcTarFrntBlowrUds_Val: accessed-variable=HvacBlowr_prcTarFrntBlowrUds.Val
            SEND_HvacBlowr_uTarFrntBlowrUds_Val: accessed-variable=HvacBlowr_uTarFrntBlowrUds.Val
            SEND_HvacDampr_uActDrvrRcrltnMotUds_Val: accessed-variable=HvacDampr_uActDrvrRcrltnMotUds.Val
            SEND_HvacDampr_uActModMotUds_Val: accessed-variable=HvacDampr_uActModMotUds.Val
            SEND_HvacDampr_uActPassMixMotUds_Val: accessed-variable=HvacDampr_uActPassMixMotUds.Val
            SEND_HvacDampr_uActPassRcrltnMotUds_Val: accessed-variable=HvacDampr_uActPassRcrltnMotUds.Val
            SEND_HvacDampr_uActPsgrMixMotUds_Val: accessed-variable=HvacDampr_uActPsgrMixMotUds.Val
            SEND_HvacDampr_uActRcrltnMotUds_Val: accessed-variable=HvacDampr_uActRcrltnMotUds.Val
            SEND_HvacDampr_uTarDrvrMixMotUds_Val: accessed-variable=HvacDampr_uTarDrvrMixMotUds.Val
            SEND_HvacDampr_uTarDrvrRcrltnMotUds_Val: accessed-variable=HvacDampr_uTarDrvrRcrltnMotUds.Val
            SEND_HvacDampr_uTarModMotUds_Val: accessed-variable=HvacDampr_uTarModMotUds.Val
            SEND_HvacDampr_uTarPassMixMotUds_Val: accessed-variable=HvacDampr_uTarPassMixMotUds.Val
            SEND_HvacDampr_uTarPassRcrltnMotUds_Val: accessed-variable=HvacDampr_uTarPassRcrltnMotUds.Val
            SEND_HvacDampr_uTarRcrltnMotUds_Val: accessed-variable=HvacDampr_uTarRcrltnMotUds.Val
  swc implementation HVAC_ComCnvTx_Implementation: behavior=HVAC_ComCnvTx_InternalBehavior
    code-descriptors:
      code Default: artifact-descriptors=autosar-engineering-object={short-label=Default, category=SWSRC}
package /UAES/ASW/Units
  unit DegC: display-name=DegC, factor-si-to-unit=1, offset-si-to-unit=0
  unit NoUnit: factor-si-to-unit=1, offset-si-to-unit=0
